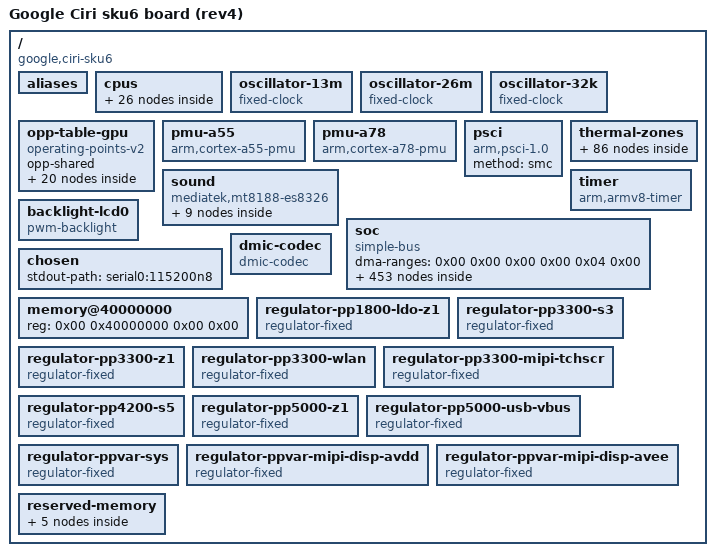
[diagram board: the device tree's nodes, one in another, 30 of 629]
/dts-v1/;

/ {
	compatible = "google,ciri-sku6", "google,ciri", "mediatek,mt8188";
	interrupt-parent = <0x01>;
	#address-cells = <0x02>;
	#size-cells = <0x02>;
	model = "Google Ciri sku6 board (rev4)";

	aliases {
		dp-intf0 = "/soc/dp-intf@1c015000";
		dp-intf1 = "/soc/dp-intf@1c113000";
		dsc0 = "/soc/dsc@1c009000";
		ethdr0 = "/soc/ethdr@1c114000";
		gce0 = "/soc/mailbox@10320000";
		gce1 = "/soc/mailbox@10330000";
		merge0 = "/soc/merge0@1c014000";
		merge1 = "/soc/merge@1c10c000";
		merge2 = "/soc/merge@1c10d000";
		merge3 = "/soc/merge@1c10e000";
		merge4 = "/soc/merge@1c10f000";
		merge5 = "/soc/merge@1c110000";
		mutex0 = "/soc/mutex@1c016000";
		mutex1 = "/soc/mutex@1c101000";
		padding0 = "/soc/padding@1c11d000";
		padding1 = "/soc/padding@1c11e000";
		padding2 = "/soc/padding@1c11f000";
		padding3 = "/soc/padding@1c120000";
		padding4 = "/soc/padding@1c121000";
		padding5 = "/soc/padding@1c122000";
		padding6 = "/soc/padding@1c123000";
		padding7 = "/soc/padding@1c124000";
		vdo1-rdma0 = "/soc/rdma@1c104000";
		vdo1-rdma1 = "/soc/rdma@1c105000";
		vdo1-rdma2 = "/soc/rdma@1c106000";
		vdo1-rdma3 = "/soc/rdma@1c107000";
		vdo1-rdma4 = "/soc/rdma@1c108000";
		vdo1-rdma5 = "/soc/rdma@1c109000";
		vdo1-rdma6 = "/soc/rdma@1c10a000";
		vdo1-rdma7 = "/soc/rdma@1c10b000";
		dsi0 = "/soc/dsi@1c008000";
		i2c0 = "/soc/i2c@11280000";
		i2c1 = "/soc/i2c@11e00000";
		i2c2 = "/soc/i2c@11281000";
		i2c3 = "/soc/i2c@11282000";
		i2c4 = "/soc/i2c@11e01000";
		i2c5 = "/soc/i2c@11ec0000";
		i2c6 = "/soc/i2c@11ec1000";
		mmc0 = "/soc/mmc@11230000";
		serial0 = "/soc/serial@11001100";
	};

	cpus {
		#address-cells = <0x01>;
		#size-cells = <0x00>;

		cpu@0 {
			device_type = "cpu";
			compatible = "arm,cortex-a55";
			reg = <0x00>;
			enable-method = "psci";
			clock-frequency = <0x77359400>;
			capacity-dmips-mhz = <0x11a>;
			cpu-idle-states = <0x02 0x03>;
			i-cache-size = <0x8000>;
			i-cache-line-size = <0x40>;
			i-cache-sets = <0x80>;
			d-cache-size = <0x8000>;
			d-cache-line-size = <0x40>;
			d-cache-sets = <0x80>;
			next-level-cache = <0x04>;
			performance-domains = <0x05 0x00>;
			#cooling-cells = <0x02>;
			phandle = <0x09>;
		};

		cpu@100 {
			device_type = "cpu";
			compatible = "arm,cortex-a55";
			reg = <0x100>;
			enable-method = "psci";
			clock-frequency = <0x77359400>;
			capacity-dmips-mhz = <0x11a>;
			cpu-idle-states = <0x02 0x03>;
			i-cache-size = <0x8000>;
			i-cache-line-size = <0x40>;
			i-cache-sets = <0x80>;
			d-cache-size = <0x8000>;
			d-cache-line-size = <0x40>;
			d-cache-sets = <0x80>;
			next-level-cache = <0x04>;
			performance-domains = <0x05 0x00>;
			#cooling-cells = <0x02>;
			phandle = <0x0a>;
		};

		cpu@200 {
			device_type = "cpu";
			compatible = "arm,cortex-a55";
			reg = <0x200>;
			enable-method = "psci";
			clock-frequency = <0x77359400>;
			capacity-dmips-mhz = <0x11a>;
			cpu-idle-states = <0x02 0x03>;
			i-cache-size = <0x8000>;
			i-cache-line-size = <0x40>;
			i-cache-sets = <0x80>;
			d-cache-size = <0x8000>;
			d-cache-line-size = <0x40>;
			d-cache-sets = <0x80>;
			next-level-cache = <0x04>;
			performance-domains = <0x05 0x00>;
			#cooling-cells = <0x02>;
			phandle = <0x0b>;
		};

		cpu@300 {
			device_type = "cpu";
			compatible = "arm,cortex-a55";
			reg = <0x300>;
			enable-method = "psci";
			clock-frequency = <0x77359400>;
			capacity-dmips-mhz = <0x11a>;
			cpu-idle-states = <0x02 0x03>;
			i-cache-size = <0x8000>;
			i-cache-line-size = <0x40>;
			i-cache-sets = <0x80>;
			d-cache-size = <0x8000>;
			d-cache-line-size = <0x40>;
			d-cache-sets = <0x80>;
			next-level-cache = <0x04>;
			performance-domains = <0x05 0x00>;
			#cooling-cells = <0x02>;
			phandle = <0x0c>;
		};

		cpu@400 {
			device_type = "cpu";
			compatible = "arm,cortex-a55";
			reg = <0x400>;
			enable-method = "psci";
			clock-frequency = <0x77359400>;
			capacity-dmips-mhz = <0x11a>;
			cpu-idle-states = <0x02 0x03>;
			i-cache-size = <0x8000>;
			i-cache-line-size = <0x40>;
			i-cache-sets = <0x80>;
			d-cache-size = <0x8000>;
			d-cache-line-size = <0x40>;
			d-cache-sets = <0x80>;
			next-level-cache = <0x04>;
			performance-domains = <0x05 0x00>;
			#cooling-cells = <0x02>;
			phandle = <0x0d>;
		};

		cpu@500 {
			device_type = "cpu";
			compatible = "arm,cortex-a55";
			reg = <0x500>;
			enable-method = "psci";
			clock-frequency = <0x77359400>;
			capacity-dmips-mhz = <0x11a>;
			cpu-idle-states = <0x02 0x03>;
			i-cache-size = <0x8000>;
			i-cache-line-size = <0x40>;
			i-cache-sets = <0x80>;
			d-cache-size = <0x8000>;
			d-cache-line-size = <0x40>;
			d-cache-sets = <0x80>;
			next-level-cache = <0x04>;
			performance-domains = <0x05 0x00>;
			#cooling-cells = <0x02>;
			phandle = <0x0e>;
		};

		cpu@600 {
			device_type = "cpu";
			compatible = "arm,cortex-a78";
			reg = <0x600>;
			enable-method = "psci";
			clock-frequency = <0x9af8da00>;
			capacity-dmips-mhz = <0x400>;
			cpu-idle-states = <0x06 0x07>;
			i-cache-size = <0x10000>;
			i-cache-line-size = <0x40>;
			i-cache-sets = <0x100>;
			d-cache-size = <0x10000>;
			d-cache-line-size = <0x40>;
			d-cache-sets = <0x100>;
			next-level-cache = <0x08>;
			performance-domains = <0x05 0x01>;
			#cooling-cells = <0x02>;
			phandle = <0x0f>;
		};

		cpu@700 {
			device_type = "cpu";
			compatible = "arm,cortex-a78";
			reg = <0x700>;
			enable-method = "psci";
			clock-frequency = <0x9af8da00>;
			capacity-dmips-mhz = <0x400>;
			cpu-idle-states = <0x06 0x07>;
			i-cache-size = <0x10000>;
			i-cache-line-size = <0x40>;
			i-cache-sets = <0x100>;
			d-cache-size = <0x10000>;
			d-cache-line-size = <0x40>;
			d-cache-sets = <0x100>;
			next-level-cache = <0x08>;
			performance-domains = <0x05 0x01>;
			#cooling-cells = <0x02>;
			phandle = <0x10>;
		};

		cpu-map {

			cluster0 {

				core0 {
					cpu = <0x09>;
				};

				core1 {
					cpu = <0x0a>;
				};

				core2 {
					cpu = <0x0b>;
				};

				core3 {
					cpu = <0x0c>;
				};

				core4 {
					cpu = <0x0d>;
				};

				core5 {
					cpu = <0x0e>;
				};

				core6 {
					cpu = <0x0f>;
				};

				core7 {
					cpu = <0x10>;
				};
			};
		};

		idle-states {
			entry-method = "psci";

			cpu-off-l {
				compatible = "arm,idle-state";
				arm,psci-suspend-param = <0x10000>;
				local-timer-stop;
				entry-latency-us = <0x32>;
				exit-latency-us = <0x5f>;
				min-residency-us = <0x244>;
				phandle = <0x02>;
			};

			cpu-off-b {
				compatible = "arm,idle-state";
				arm,psci-suspend-param = <0x10000>;
				local-timer-stop;
				entry-latency-us = <0x2d>;
				exit-latency-us = <0x8c>;
				min-residency-us = <0x2e4>;
				phandle = <0x06>;
			};

			cluster-off-l {
				compatible = "arm,idle-state";
				arm,psci-suspend-param = <0x1010010>;
				local-timer-stop;
				entry-latency-us = <0x37>;
				exit-latency-us = <0x9b>;
				min-residency-us = <0x348>;
				phandle = <0x03>;
			};

			cluster-off-b {
				compatible = "arm,idle-state";
				arm,psci-suspend-param = <0x1010010>;
				local-timer-stop;
				entry-latency-us = <0x32>;
				exit-latency-us = <0xc8>;
				min-residency-us = <0x3e8>;
				phandle = <0x07>;
			};
		};

		l2-cache0 {
			compatible = "cache";
			cache-level = <0x02>;
			cache-size = <0x20000>;
			cache-line-size = <0x40>;
			cache-sets = <0x200>;
			next-level-cache = <0x11>;
			cache-unified;
			phandle = <0x04>;
		};

		l2-cache1 {
			compatible = "cache";
			cache-level = <0x02>;
			cache-size = <0x40000>;
			cache-line-size = <0x40>;
			cache-sets = <0x200>;
			next-level-cache = <0x11>;
			cache-unified;
			phandle = <0x08>;
		};

		l3-cache {
			compatible = "cache";
			cache-level = <0x03>;
			cache-size = <0x200000>;
			cache-line-size = <0x40>;
			cache-sets = <0x800>;
			cache-unified;
			phandle = <0x11>;
		};
	};

	oscillator-13m {
		compatible = "fixed-clock";
		#clock-cells = <0x00>;
		clock-frequency = <0xc65d40>;
		clock-output-names = "clk13m";
		phandle = <0x40>;
	};

	oscillator-26m {
		compatible = "fixed-clock";
		#clock-cells = <0x00>;
		clock-frequency = <0x18cba80>;
		clock-output-names = "clk26m";
		phandle = <0x43>;
	};

	oscillator-32k {
		compatible = "fixed-clock";
		#clock-cells = <0x00>;
		clock-frequency = <0x8000>;
		clock-output-names = "clk32k";
	};

	opp-table-gpu {
		compatible = "operating-points-v2";
		opp-shared;
		phandle = <0x77>;

		opp-390000000 {
			opp-hz = <0x00 0x173eed80>;
			opp-microvolt = <0x8c618>;
			opp-supported-hw = <0xff>;
		};

		opp-431000000 {
			opp-hz = <0x00 0x19b089c0>;
			opp-microvolt = <0x8f6ec>;
			opp-supported-hw = <0xff>;
		};

		opp-473000000 {
			opp-hz = <0x00 0x1c316840>;
			opp-microvolt = <0x927c0>;
			opp-supported-hw = <0xff>;
		};

		opp-515000000 {
			opp-hz = <0x00 0x1eb246c0>;
			opp-microvolt = <0x95894>;
			opp-supported-hw = <0xff>;
		};

		opp-556000000 {
			opp-hz = <0x00 0x2123e300>;
			opp-microvolt = <0x98968>;
			opp-supported-hw = <0xff>;
		};

		opp-598000000 {
			opp-hz = <0x00 0x23a4c180>;
			opp-microvolt = <0x9ba3c>;
			opp-supported-hw = <0xff>;
		};

		opp-640000000 {
			opp-hz = <0x00 0x2625a000>;
			opp-microvolt = <0x9eb10>;
			opp-supported-hw = <0xff>;
		};

		opp-670000000 {
			opp-hz = <0x00 0x27ef6380>;
			opp-microvolt = <0xa1be4>;
			opp-supported-hw = <0xff>;
		};

		opp-700000000 {
			opp-hz = <0x00 0x29b92700>;
			opp-microvolt = <0xa4cb8>;
			opp-supported-hw = <0xff>;
		};

		opp-730000000 {
			opp-hz = <0x00 0x2b82ea80>;
			opp-microvolt = <0xa7d8c>;
			opp-supported-hw = <0xff>;
		};

		opp-760000000 {
			opp-hz = <0x00 0x2d4cae00>;
			opp-microvolt = <0xaae60>;
			opp-supported-hw = <0xff>;
		};

		opp-790000000 {
			opp-hz = <0x00 0x2f167180>;
			opp-microvolt = <0xadf34>;
			opp-supported-hw = <0xff>;
		};

		opp-835000000 {
			opp-hz = <0x00 0x31c516c0>;
			opp-microvolt = <0xb2872>;
			opp-supported-hw = <0xff>;
		};

		opp-880000000 {
			opp-hz = <0x00 0x3473bc00>;
			opp-microvolt = <0xb71b0>;
			opp-supported-hw = <0xff>;
		};

		opp-915000000 {
			opp-hz = <0x00 0x3689cac0>;
			opp-microvolt = <0xbd358>;
			opp-supported-hw = <0x8f>;
		};

		opp-915000000-5 {
			opp-hz = <0x00 0x3689cac0>;
			opp-microvolt = <0xba284>;
			opp-supported-hw = <0x30>;
		};

		opp-915000000-6 {
			opp-hz = <0x00 0x3689cac0>;
			opp-microvolt = <0xb71b0>;
			opp-supported-hw = <0x70>;
		};

		opp-950000000 {
			opp-hz = <0x00 0x389fd980>;
			opp-microvolt = <0xf5000>;
			opp-supported-hw = <0x8f>;
		};

		opp-950000000-5 {
			opp-hz = <0x00 0x389fd980>;
			opp-microvolt = <0xbd358>;
			opp-supported-hw = <0x30>;
		};

		opp-950000000-6 {
			opp-hz = <0x00 0x389fd980>;
			opp-microvolt = <0xb71b0>;
			opp-supported-hw = <0x70>;
		};
	};

	pmu-a55 {
		compatible = "arm,cortex-a55-pmu";
		interrupt-parent = <0x01>;
		interrupts = <0x01 0x07 0x04 0x12>;
	};

	pmu-a78 {
		compatible = "arm,cortex-a78-pmu";
		interrupt-parent = <0x01>;
		interrupts = <0x01 0x07 0x04 0x13>;
	};

	psci {
		compatible = "arm,psci-1.0";
		method = "smc";
	};

	sound {
		mediatek,platform = <0x14>;
		status = "okay";
		pinctrl-names = "aud_etdm_hp_on", "aud_etdm_hp_off", "aud_etdm_spk_on", "aud_etdm_spk_off", "aud_mtkaif_on", "aud_mtkaif_off";
		pinctrl-0 = <0x15>;
		pinctrl-1 = <0x16>;
		pinctrl-2 = <0x17>;
		pinctrl-3 = <0x18>;
		pinctrl-4 = <0x19>;
		pinctrl-5 = <0x1a>;
		mediatek,adsp = <0x1b>;
		compatible = "mediatek,mt8188-es8326";
		model = "mt8188_tas2563_8326";
		audio-routing = "ETDM1_OUT", "ETDM_SPK_PIN", "ETDM2_OUT", "ETDM_HP_PIN", "ETDM1_IN", "ETDM_SPK_PIN", "ETDM2_IN", "ETDM_HP_PIN", "ADDA Capture", "MTKAIF_PIN", "Headphone Jack", "HPOL", "Headphone Jack", "HPOR", "MIC1", "Headset Mic";

		dai-link-0 {
			link-name = "ETDM2_OUT_BE";
			mediatek,clk-provider = "cpu";

			codec {
				sound-dai = <0x1d>;
			};
		};

		dai-link-1 {
			link-name = "ETDM2_IN_BE";
			mediatek,clk-provider = "cpu";

			codec {
				sound-dai = <0x1d>;
			};
		};

		dai-link-2 {
			link-name = "ETDM1_OUT_BE";
			dai-format = "i2s";
			mediatek,clk-provider = "cpu";

			codec {
				sound-dai = <0x1c>;
			};
		};

		dai-link-3 {
			link-name = "ETDM1_IN_BE";
			dai-format = "i2s";
			mediatek,clk-provider = "cpu";
		};

		dai-link-4 {
			link-name = "DPTX_BE";

			codec {
				sound-dai = <0x1e>;
			};
		};
	};

	thermal-zones {

		cpu-little0-thermal {
			polling-delay = <0x3e8>;
			polling-delay-passive = <0x96>;
			thermal-sensors = <0x1f 0x00>;

			trips {

				trip-alert0 {
					temperature = <0x15f90>;
					hysteresis = <0x7d0>;
					type = "passive";
					phandle = <0x20>;
				};

				trip-alert1 {
					temperature = <0x17318>;
					hysteresis = <0x7d0>;
					type = "hot";
				};

				trip-crit {
					temperature = <0x186a0>;
					hysteresis = <0x00>;
					type = "critical";
				};
			};

			cooling-maps {

				map0 {
					trip = <0x20>;
					cooling-device = <0x09 0xffffffff 0xffffffff 0x0a 0xffffffff 0xffffffff 0x0b 0xffffffff 0xffffffff 0x0c 0xffffffff 0xffffffff 0x0d 0xffffffff 0xffffffff 0x0e 0xffffffff 0xffffffff>;
				};
			};
		};

		cpu-little1-thermal {
			polling-delay = <0x3e8>;
			polling-delay-passive = <0x96>;
			thermal-sensors = <0x1f 0x01>;

			trips {

				trip-alert0 {
					temperature = <0x15f90>;
					hysteresis = <0x7d0>;
					type = "passive";
					phandle = <0x21>;
				};

				trip-alert1 {
					temperature = <0x17318>;
					hysteresis = <0x7d0>;
					type = "hot";
				};

				trip-crit {
					temperature = <0x186a0>;
					hysteresis = <0x00>;
					type = "critical";
				};
			};

			cooling-maps {

				map0 {
					trip = <0x21>;
					cooling-device = <0x09 0xffffffff 0xffffffff 0x0a 0xffffffff 0xffffffff 0x0b 0xffffffff 0xffffffff 0x0c 0xffffffff 0xffffffff 0x0d 0xffffffff 0xffffffff 0x0e 0xffffffff 0xffffffff>;
				};
			};
		};

		cpu-little2-thermal {
			polling-delay = <0x3e8>;
			polling-delay-passive = <0x96>;
			thermal-sensors = <0x1f 0x02>;

			trips {

				trip-alert0 {
					temperature = <0x15f90>;
					hysteresis = <0x7d0>;
					type = "passive";
					phandle = <0x22>;
				};

				trip-alert1 {
					temperature = <0x17318>;
					hysteresis = <0x7d0>;
					type = "hot";
				};

				trip-crit {
					temperature = <0x186a0>;
					hysteresis = <0x00>;
					type = "critical";
				};
			};

			cooling-maps {

				map0 {
					trip = <0x22>;
					cooling-device = <0x09 0xffffffff 0xffffffff 0x0a 0xffffffff 0xffffffff 0x0b 0xffffffff 0xffffffff 0x0c 0xffffffff 0xffffffff 0x0d 0xffffffff 0xffffffff 0x0e 0xffffffff 0xffffffff>;
				};
			};
		};

		cpu-little3-thermal {
			polling-delay = <0x3e8>;
			polling-delay-passive = <0x96>;
			thermal-sensors = <0x1f 0x03>;

			trips {

				trip-alert0 {
					temperature = <0x15f90>;
					hysteresis = <0x7d0>;
					type = "passive";
					phandle = <0x23>;
				};

				trip-alert1 {
					temperature = <0x17318>;
					hysteresis = <0x7d0>;
					type = "hot";
				};

				trip-crit {
					temperature = <0x186a0>;
					hysteresis = <0x00>;
					type = "critical";
				};
			};

			cooling-maps {

				map0 {
					trip = <0x23>;
					cooling-device = <0x09 0xffffffff 0xffffffff 0x0a 0xffffffff 0xffffffff 0x0b 0xffffffff 0xffffffff 0x0c 0xffffffff 0xffffffff 0x0d 0xffffffff 0xffffffff 0x0e 0xffffffff 0xffffffff>;
				};
			};
		};

		cpu-big0-thermal {
			polling-delay = <0x3e8>;
			polling-delay-passive = <0x64>;
			thermal-sensors = <0x1f 0x04>;

			trips {

				trip-alert0 {
					temperature = <0x15f90>;
					hysteresis = <0x7d0>;
					type = "passive";
					phandle = <0x24>;
				};

				trip-alert1 {
					temperature = <0x17318>;
					hysteresis = <0x7d0>;
					type = "hot";
				};

				trip-crit {
					temperature = <0x186a0>;
					hysteresis = <0x00>;
					type = "critical";
				};
			};

			cooling-maps {

				map0 {
					trip = <0x24>;
					cooling-device = <0x0f 0xffffffff 0xffffffff 0x10 0xffffffff 0xffffffff>;
				};
			};
		};

		cpu-big1-thermal {
			polling-delay = <0x3e8>;
			polling-delay-passive = <0x64>;
			thermal-sensors = <0x1f 0x05>;

			trips {

				trip-alert0 {
					temperature = <0x15f90>;
					hysteresis = <0x7d0>;
					type = "passive";
					phandle = <0x25>;
				};

				trip-alert1 {
					temperature = <0x17318>;
					hysteresis = <0x7d0>;
					type = "hot";
				};

				trip-crit {
					temperature = <0x186a0>;
					hysteresis = <0x00>;
					type = "critical";
				};
			};

			cooling-maps {

				map0 {
					trip = <0x25>;
					cooling-device = <0x0f 0xffffffff 0xffffffff 0x10 0xffffffff 0xffffffff>;
				};
			};
		};

		apu-thermal {
			polling-delay = <0x3e8>;
			polling-delay-passive = <0xfa>;
			thermal-sensors = <0x26 0x00>;

			trips {

				trip-alert0 {
					temperature = <0x14c08>;
					hysteresis = <0x7d0>;
					type = "passive";
				};

				trip-alert1 {
					temperature = <0x17318>;
					hysteresis = <0x7d0>;
					type = "hot";
				};

				trip-crit {
					temperature = <0x186a0>;
					hysteresis = <0x00>;
					type = "critical";
				};
			};
		};

		gpu-thermal {
			polling-delay = <0x3e8>;
			polling-delay-passive = <0xfa>;
			thermal-sensors = <0x26 0x01>;

			trips {

				trip-alert0 {
					temperature = <0x14c08>;
					hysteresis = <0x7d0>;
					type = "passive";
					phandle = <0x27>;
				};

				trip-alert1 {
					temperature = <0x17318>;
					hysteresis = <0x7d0>;
					type = "hot";
				};

				trip-crit {
					temperature = <0x186a0>;
					hysteresis = <0x00>;
					type = "critical";
				};
			};

			cooling-maps {

				map0 {
					trip = <0x27>;
					cooling-device = <0x28 0xffffffff 0xffffffff>;
				};
			};
		};

		gpu1-thermal {
			polling-delay = <0x3e8>;
			polling-delay-passive = <0xfa>;
			thermal-sensors = <0x26 0x02>;

			trips {

				trip-alert0 {
					temperature = <0x14c08>;
					hysteresis = <0x7d0>;
					type = "passive";
					phandle = <0x29>;
				};

				trip-alert1 {
					temperature = <0x17318>;
					hysteresis = <0x7d0>;
					type = "hot";
				};

				trip-crit {
					temperature = <0x186a0>;
					hysteresis = <0x00>;
					type = "critical";
				};
			};

			cooling-maps {

				map0 {
					trip = <0x29>;
					cooling-device = <0x28 0xffffffff 0xffffffff>;
				};
			};
		};

		adsp-thermal {
			polling-delay = <0x3e8>;
			polling-delay-passive = <0xfa>;
			thermal-sensors = <0x26 0x03>;

			trips {

				trip-alert0 {
					temperature = <0x14c08>;
					hysteresis = <0x7d0>;
					type = "passive";
				};

				trip-alert1 {
					temperature = <0x17318>;
					hysteresis = <0x7d0>;
					type = "hot";
				};

				trip-crit {
					temperature = <0x186a0>;
					hysteresis = <0x00>;
					type = "critical";
				};
			};
		};

		vdo-thermal {
			polling-delay = <0x3e8>;
			polling-delay-passive = <0xfa>;
			thermal-sensors = <0x26 0x04>;

			trips {

				trip-alert0 {
					temperature = <0x14c08>;
					hysteresis = <0x7d0>;
					type = "passive";
				};

				trip-alert1 {
					temperature = <0x17318>;
					hysteresis = <0x7d0>;
					type = "hot";
				};

				trip-crit {
					temperature = <0x186a0>;
					hysteresis = <0x00>;
					type = "critical";
				};
			};
		};

		infra-thermal {
			polling-delay = <0x3e8>;
			polling-delay-passive = <0xfa>;
			thermal-sensors = <0x26 0x05>;

			trips {

				trip-alert0 {
					temperature = <0x14c08>;
					hysteresis = <0x7d0>;
					type = "passive";
				};

				trip-alert1 {
					temperature = <0x17318>;
					hysteresis = <0x7d0>;
					type = "hot";
				};

				trip-crit {
					temperature = <0x186a0>;
					hysteresis = <0x00>;
					type = "critical";
				};
			};
		};

		cam1-thermal {
			polling-delay = <0x3e8>;
			polling-delay-passive = <0xfa>;
			thermal-sensors = <0x26 0x06>;

			trips {

				trip-alert0 {
					temperature = <0x14c08>;
					hysteresis = <0x7d0>;
					type = "passive";
				};

				trip-alert1 {
					temperature = <0x17318>;
					hysteresis = <0x7d0>;
					type = "hot";
				};

				trip-crit {
					temperature = <0x186a0>;
					hysteresis = <0x00>;
					type = "critical";
				};
			};
		};

		cam2-thermal {
			polling-delay = <0x3e8>;
			polling-delay-passive = <0xfa>;
			thermal-sensors = <0x26 0x07>;

			trips {

				trip-alert0 {
					temperature = <0x14c08>;
					hysteresis = <0x7d0>;
					type = "passive";
				};

				trip-alert1 {
					temperature = <0x17318>;
					hysteresis = <0x7d0>;
					type = "hot";
				};

				trip-crit {
					temperature = <0x186a0>;
					hysteresis = <0x00>;
					type = "critical";
				};
			};
		};
	};

	timer {
		compatible = "arm,armv8-timer";
		interrupt-parent = <0x01>;
		interrupts = <0x01 0x0d 0x04 0x00 0x01 0x0e 0x04 0x00 0x01 0x0b 0x04 0x00 0x01 0x0a 0x04 0x00>;
		clock-frequency = <0xc65d40>;
	};

	soc {
		#address-cells = <0x02>;
		#size-cells = <0x02>;
		compatible = "simple-bus";
		dma-ranges = <0x00 0x00 0x00 0x00 0x04 0x00>;
		ranges;

		performance-controller@11bc10 {
			compatible = "mediatek,cpufreq-hw";
			reg = <0x00 0x11bc10 0x00 0x120 0x00 0x11bd30 0x00 0x120>;
			#performance-domain-cells = <0x01>;
			phandle = <0x05>;
		};

		interrupt-controller@c000000 {
			compatible = "arm,gic-v3";
			#interrupt-cells = <0x04>;
			#redistributor-regions = <0x01>;
			interrupt-parent = <0x01>;
			interrupt-controller;
			reg = <0x00 0xc000000 0x00 0x40000 0x00 0xc040000 0x00 0x200000>;
			interrupts = <0x01 0x09 0x04 0x00>;
			phandle = <0x01>;

			ppi-partitions {

				interrupt-partition-0 {
					affinity = <0x09 0x0a 0x0b 0x0c 0x0d 0x0e>;
					phandle = <0x12>;
				};

				interrupt-partition-1 {
					affinity = <0x0f 0x10>;
					phandle = <0x13>;
				};
			};
		};

		syscon@10000000 {
			compatible = "mediatek,mt8188-topckgen", "syscon";
			reg = <0x00 0x10000000 0x00 0x1000>;
			#clock-cells = <0x01>;
			phandle = <0x2d>;
		};

		syscon@10001000 {
			compatible = "mediatek,mt8188-infracfg-ao", "syscon";
			reg = <0x00 0x10001000 0x00 0x1000>;
			#clock-cells = <0x01>;
			#reset-cells = <0x01>;
			phandle = <0x2e>;
		};

		syscon@10003000 {
			compatible = "mediatek,mt8188-pericfg", "syscon";
			reg = <0x00 0x10003000 0x00 0x1000>;
			#clock-cells = <0x01>;
			phandle = <0x57>;
		};

		pinctrl@10005000 {
			compatible = "mediatek,mt8188-pinctrl";
			reg = <0x00 0x10005000 0x00 0x1000 0x00 0x11c00000 0x00 0x1000 0x00 0x11e10000 0x00 0x1000 0x00 0x11e20000 0x00 0x1000 0x00 0x11ea0000 0x00 0x1000 0x00 0x1000b000 0x00 0x1000>;
			reg-names = "iocfg0", "iocfg_rm", "iocfg_lt", "iocfg_lm", "iocfg_rt", "eint";
			gpio-controller;
			#gpio-cells = <0x02>;
			gpio-ranges = <0x2a 0x00 0x00 0xb0>;
			interrupt-controller;
			interrupts = <0x00 0xeb 0x04 0x00>;
			#interrupt-cells = <0x02>;
			gpio-line-names = "GSC_AP_INT_ODL", "AP_DISP_BKLTEN", "", "EN_PPVAR_MIPI_DISP", "EN_PPVAR_MIPI_DISP_150MA", "TCHSCR_RST_1V8_L", "", "", "", "", "", "I2S_SPKR_DATAOUT", "EN_PP3300_WLAN_X", "WIFI_KILL_1V8_L", "BT_KILL_1V8_L", "AP_FLASH_WP_L", "", "", "WCAM_PWDN_L", "WCAM_RST_L", "UCAM_PWDM_L", "UCAM_RST_L", "WCAM_24M_CLK", "UCAM_24M_CLK", "MT6319_INT", "DISP_RST_1V8_L", "DSIO_DSI_TE", "", "TP", "MIPI_BL_PWM_1V8", "", "UART_AP_TX_GSC_RX", "UART_GSC_TX_AP_RX", "UART_SSPM_TX_DBGCON_RX", "UART_DBGCON_TX_SSPM_RX", "UART_ADSP_TX_DBGCON_RX", "UART_DBGCON_TX_ADSP_RX", "JTAG_AP_TMS", "JTAG_AP_TCK", "JTAG_AP_TDI", "JTAG_AP_TDO", "JTAG_AP_TRST", "AP_KPCOL0", "TP", "", "TP", "EC_AP_HPD_OD", "PCIE_WAKE_1V8_ODL", "PCIE_RST_1V8_L", "PCIE_CLKREQ_1V8_ODL", "", "", "", "", "", "AP_I2C_AUD_SCL_1V8", "AP_I2C_AUD_SDA_1V8", "AP_I2C_TPM_SCL_1V8", "AP_I2C_TPM_SDA_1V8", "AP_I2C_TCHSCR_SCL_1V8", "AP_I2C_TCHSCR_SDA_1V8", "AP_I2C_PMIC_SAR_SCL_1V8", "AP_I2C_PMIC_SAR_SDA_1V8", "AP_I2C_EC_HID_KB_SCL_1V8", "AP_I2C_EC_HID_KB_SDA_1V8", "AP_I2C_UCAM_SCL_1V8", "AP_I2C_UCAM_SDA_1V8", "AP_I2C_WCAM_SCL_1V8", "AP_I2C_WCAM_SDA_1V8", "SPI_AP_CS_EC_L", "SPI_AP_CLK_EC", "SPI_AP_DO_EC_DI", "SPI_AP_DI_EC_DO", "TP", "TP", "SPI_AP_CS_TCHSCR_L", "SPI_AP_CLK_TCHSCR", "SPI_AP_DO_TCHSCR_DI", "SPI_AP_DI_TCHSCR_DO", "TP", "TP", "TP", "TP", "", "", "", "TP", "", "", "", "", "", "PWRAP_SPI_CS_L", "PWRAP_SPI_CK", "PWRAP_SPI_MOSI", "PWRAP_SPI_MISO", "SRCLKENA0", "SRCLKENA1", "SCP_VREQ_VAO", "AP_RTC_CLK32K", "AP_PMIC_WDTRST_L", "AUD_CLK_MOSI", "AUD_SYNC_MOSI", "AUD_DAT_MOSI0", "AUD_DAT_MOSI1", "AUD_DAT_MISO0", "AUD_DAT_MISO1", "", "HP_INT_ODL", "SPKR_INT_ODL", "I2S_HP_DATAIN", "EN_SPKR", "I2S_SPKR_MCLK", "I2S_SPKR_BCLK", "I2S_HP_MCLK", "I2S_HP_BCLK", "I2S_HP_LRCK", "I2S_HP_DATAOUT", "RST_SPKR_L", "I2S_SPKR_LRCK", "I2S_SPKR_DATAIN", "", "", "", "", "SPI_AP_CLK_ROM", "SPI_AP_CS_ROM_L", "SPI_AP_DO_ROM_DI", "SPI_AP_DI_ROM_DO", "TP", "TP", "", "", "", "", "", "", "", "", "EN_PP2800A_UCAM_X", "EN_PP1200_UCAM_X", "EN_PP2800A_WCAM_X", "EN_PP1100_WCAM_X", "TCHSCR_INT_1V8_L", "", "MT7921_PMU_EN_1V8", "", "AP_EC_WARM_RST_REQ", "EC_AP_HID_INT_ODL", "EC_AP_INT_ODL", "AP_XHCI_INIT_DONE", "EMMC_DAT7", "EMMC_DAT6", "EMMC_DAT5", "EMMC_DAT4", "EMMC_RST_L", "EMMC_CMD", "EMMC_CLK", "EMMC_DAT3", "EMMC_DAT2", "EMMC_DAT1", "EMMC_DAT0", "EMMC_DSL", "", "", "", "", "", "", "", "", "USB3_HUB_RST_L", "EC_AP_RSVD0_ODL", "", "", "SPMI_SCL", "SPMI_SDA";
			phandle = <0x2a>;

			adsp-uart-pins {
				phandle = <0x4b>;

				pins-bus {
					pinmux = <0x2303 0x2403>;
				};
			};

			aud-etdm-hp-on-pins {
				phandle = <0x15>;

				pins-bus {
					pinmux = <0x6e01 0x7301 0x7401 0x7501>;
				};

				pins-mclk {
					pinmux = <0x7201>;
				};
			};

			aud-etdm-hp-off-pins {
				phandle = <0x16>;

				pins-bus {
					pinmux = <0x6e00 0x7300 0x7400 0x7500>;
					bias-pull-down;
					input-enable;
				};

				pins-mclk {
					pinmux = <0x7200>;
					bias-pull-down;
					input-enable;
				};
			};

			aud-etdm-spk-on-pins {
				phandle = <0x17>;

				pins-bus {
					pinmux = <0xb03 0x7104 0x7704 0x7804>;
					drive-strength = <0x08>;
				};
			};

			aud-etdm-spk-off-pins {
				phandle = <0x18>;

				pins-bus {
					pinmux = <0xb00 0x7100 0x7700 0x7800>;
					bias-pull-down;
					input-enable;
				};
			};

			aud-mtkaif-on-pins {
				phandle = <0x19>;

				pins-bus {
					pinmux = <0x6501 0x6601 0x6701 0x6801 0x6901 0x6a01>;
				};
			};

			aud-mtkaif-off-pins {
				phandle = <0x1a>;

				pins-bus {
					pinmux = <0x6500 0x6600 0x6700 0x6800 0x6900 0x6a00>;
					bias-pull-down;
					input-enable;
				};
			};

			cros-ec-int-pins {
				phandle = <0x4e>;

				pins-ec-ap-int-odl {
					pinmux = <0x9500>;
					input-enable;
				};
			};

			disp-pwm0-pins {
				phandle = <0x50>;

				pins-disp-pwm0 {
					pinmux = <0x1d01>;
					output-high;
				};
			};

			disp-pwm1-pins {
				phandle = <0x51>;

				pins-disp-pwm1 {
					pinmux = <0x1e01>;
					output-high;
				};
			};

			dp-tx-hpd-pins {
				phandle = <0xad>;

				pins-dp-tx-hpd {
					pinmux = <0x2e01>;
				};
			};

			gsc-int-pins {
				phandle = <0x70>;

				pins-gsc-ap-int-odl {
					pinmux = <0x00>;
					input-enable;
				};
			};

			i2c0-pins {
				phandle = <0x62>;

				pins-bus {
					pinmux = <0x3801 0x3701>;
				};
			};

			i2c1-pins {
				phandle = <0x6f>;

				pins-bus {
					pinmux = <0x3a01 0x3901>;
				};
			};

			i2c2-pins {
				phandle = <0x64>;

				pins-bus {
					pinmux = <0x3c01 0x3b01>;
					bias-disable;
					drive-strength = <0x0c>;
				};
			};

			i2c3-pins {
				phandle = <0x65>;

				pins-bus {
					pinmux = <0x3e01 0x3d01>;
				};
			};

			i2c4-pins {
				phandle = <0x71>;

				pins-bus {
					pinmux = <0x4001 0x3f01>;
				};
			};

			i2c5-pins {
				phandle = <0x73>;

				pins-bus {
					pinmux = <0x4201 0x4101>;
				};
			};

			i2c6-pins {
				phandle = <0x74>;

				pins-bus {
					pinmux = <0x4401 0x4301>;
				};
			};

			mipi-disp-avdd-en-pins {
				phandle = <0xb3>;

				pins-en-ppvar-mipi-disp {
					pinmux = <0x300>;
					output-low;
				};
			};

			mipi-disp-avee-en-pins {
				phandle = <0xb4>;

				pins-en-ppvar-mipi-disp-150ma {
					pinmux = <0x400>;
					output-low;
				};
			};

			mipi-dsi-pins {
				phandle = <0x94>;

				pins-bus {
					pinmux = <0x100 0x1900>;
					output-low;
				};
			};

			mmc0-default-pins {
				phandle = <0x5d>;

				pins-bus {
					pinmux = <0xa101 0xa001 0x9f01 0x9e01 0x9a01 0x9901 0x9801 0x9701 0x9c01>;
					input-enable;
					drive-strength = <0x06>;
					bias-pull-up = <0x65>;
				};

				pins-clk {
					pinmux = <0x9d01>;
					drive-strength = <0x06>;
					bias-pull-down = <0x66>;
				};

				pins-rst {
					pinmux = <0x9b01>;
					drive-strength = <0x06>;
					bias-pull-up = <0x65>;
				};
			};

			mmc0-uhs-pins {
				phandle = <0x5e>;

				pins-bus {
					pinmux = <0xa101 0xa001 0x9f01 0x9e01 0x9a01 0x9901 0x9801 0x9701 0x9c01>;
					input-enable;
					drive-strength = <0x08>;
					bias-pull-up = <0x65>;
				};

				pins-clk {
					pinmux = <0x9d01>;
					drive-strength = <0x08>;
					bias-pull-down = <0x66>;
				};

				pins-ds {
					pinmux = <0xa201>;
					drive-strength = <0x08>;
					bias-pull-down = <0x66>;
				};

				pins-rst {
					pinmux = <0x9b01>;
					drive-strength = <0x08>;
					bias-pull-up = <0x65>;
				};
			};

			nor-default-pins {
				phandle = <0x6d>;

				pins-clk {
					pinmux = <0x7f02 0x7d02 0x8002>;
					bias-pull-down;
				};

				pins-cs {
					pinmux = <0x7e02>;
					bias-pull-up;
				};
			};

			pcie-default-pins {
				phandle = <0x6c>;

				pins-bus {
					pinmux = <0x2f01 0x3001 0x3101>;
				};
			};

			scp-pins {
				phandle = <0x41>;

				pins-scp-vreq {
					pinmux = <0x6201>;
					bias-disable;
				};
			};

			spi0-pins {
				phandle = <0x4d>;

				pins-bus {
					pinmux = <0x4501 0x4601 0x4701 0x4801>;
					bias-disable;
				};
			};

			spi1-default-pins {
				phandle = <0x52>;

				pins-bus {
					pinmux = <0x4b01 0x4c01 0x4d01 0x4e01>;
					bias-disable;
				};
			};

			spi1-sleep-pins {
				phandle = <0x53>;

				pins-bus {
					pinmux = <0x4b00 0x4c00 0x4d00 0x4e00>;
					bias-pull-down;
					input-enable;
				};
			};

			spi2-pins {
				phandle = <0x54>;

				pins-bus {
					pinmux = <0x4f01 0x5001 0x5101 0x5201>;
					bias-disable;
				};
			};

			uart0-pins {
				phandle = <0x4c>;

				pins-bus {
					pinmux = <0x1f01 0x2001>;
					bias-pull-up;
				};
			};

			wlan-en-pins {
				phandle = <0xb1>;

				pins-en-pp3300-wlan {
					pinmux = <0xc00>;
					output-low;
				};
			};

			audio-codec-pins {
				phandle = <0x63>;

				pins-hp-int-odl {
					pinmux = <0x6c00>;
					input-enable;
				};
			};

			speaker-en-pins {

				pins-en-spkr {
					pinmux = <0x6f00>;
				};
			};

		};

		syscon@10006000 {
			compatible = "mediatek,mt8188-scpsys", "syscon", "simple-mfd";
			reg = <0x00 0x10006000 0x00 0x1000>;

			power-controller {
				compatible = "mediatek,mt8188-power-controller";
				#address-cells = <0x01>;
				#size-cells = <0x00>;
				#power-domain-cells = <0x01>;
				phandle = <0x44>;

				power-domain@0 {
					reg = <0x00>;
					#address-cells = <0x01>;
					#size-cells = <0x00>;
					#power-domain-cells = <0x01>;
					domain-supply = <0x2b>;

					power-domain@1 {
						reg = <0x01>;
						clocks = <0x2c 0x0e 0x2d 0x14>;
						clock-names = "mfg", "alt";
						mediatek,infracfg = <0x2e>;
						#address-cells = <0x01>;
						#size-cells = <0x00>;
						#power-domain-cells = <0x01>;
						domain-supply = <0x2f>;

						power-domain@2 {
							reg = <0x02>;
							#power-domain-cells = <0x00>;
						};

						power-domain@3 {
							reg = <0x03>;
							#power-domain-cells = <0x00>;
						};

						power-domain@4 {
							reg = <0x04>;
							#power-domain-cells = <0x00>;
						};
					};
				};

				power-domain@15 {
					reg = <0x0f>;
					clocks = <0x2d 0x04 0x2d 0x07 0x2d 0x08 0x2d 0x0a 0x2d 0x33 0x2d 0x34 0x2d 0x3d 0x2d 0xb9 0x2d 0xbe 0x30 0x0c 0x30 0x0d 0x30 0x0e 0x30 0x0f 0x30 0x10 0x30 0x11 0x30 0x12 0x30 0x13 0x30 0x14 0x30 0x15 0x30 0x16 0x30 0x17 0x30 0x1a 0x30 0x1b 0x30 0x1c 0x30 0x1d 0x30 0x1e 0x30 0x1f 0x30 0x20>;
					clock-names = "top", "cam", "ccu", "img", "venc", "vdec", "wpe", "cfgck", "cfgxo", "ss-sram-cmn", "ss-sram-v0l0", "ss-sram-v0l1", "ss-sram-ve0", "ss-sram-ve1", "ss-sram-ifa", "ss-sram-cam", "ss-sram-v1l5", "ss-sram-v1l6", "ss-sram-rdr", "ss-iommu", "ss-imgcam", "ss-emi", "ss-subcmn-rdr", "ss-rsi", "ss-cmn-l4", "ss-vdec1", "ss-wpe", "ss-cvdo-ve1";
					mediatek,infracfg = <0x2e>;
					#address-cells = <0x01>;
					#size-cells = <0x00>;
					#power-domain-cells = <0x01>;

					power-domain@16 {
						reg = <0x10>;
						clocks = <0x2d 0xbb 0x2d 0xc0 0x31 0x18 0x31 0x19 0x31 0x1a 0x31 0x1b 0x31 0x1c 0x31 0x1d 0x31 0x0f>;
						clock-names = "cfgck", "cfgxo", "ss-gals", "ss-cmn", "ss-emi", "ss-iommu", "ss-larb", "ss-rsi", "ss-bus";
						mediatek,infracfg = <0x2e>;
						#address-cells = <0x01>;
						#size-cells = <0x00>;
						#power-domain-cells = <0x01>;

						power-domain@20 {
							reg = <0x14>;
							clocks = <0x2d 0xba 0x2d 0xbf 0x32 0x1c 0x32 0x1d 0x32 0x1e 0x32 0x1f>;
							clock-names = "cfgck", "cfgxo", "ss-vpp1-g5", "ss-vpp1-g6", "ss-vpp1-l5", "ss-vpp1-l6";
							mediatek,infracfg = <0x2e>;
							#power-domain-cells = <0x00>;
						};

						power-domain@22 {
							reg = <0x16>;
							clocks = <0x33 0x00>;
							clock-names = "ss-vdec1-soc-l1";
							mediatek,infracfg = <0x2e>;
							#address-cells = <0x01>;
							#size-cells = <0x00>;
							#power-domain-cells = <0x01>;

							power-domain@23 {
								reg = <0x17>;
								clocks = <0x34 0x00>;
								clock-names = "ss-vdec2-l1";
								mediatek,infracfg = <0x2e>;
								#power-domain-cells = <0x00>;
							};
						};

						power-domain@29 {
							reg = <0x1d>;
							clocks = <0x2d 0x07 0x2d 0x08 0x2d 0x09 0x2d 0xbd>;
							clock-names = "cam", "ccu", "bus", "cfgck";
							mediatek,infracfg = <0x2e>;
							#address-cells = <0x01>;
							#size-cells = <0x00>;
							#power-domain-cells = <0x01>;
							domain-supply = <0x35>;

							power-domain@30 {
								reg = <0x1e>;
								clocks = <0x36 0x00 0x36 0x01 0x36 0x16 0x36 0x17 0x36 0x18>;
								clock-names = "ss-cam-l13", "ss-cam-l14", "ss-cam-mm0", "ss-cam-mm1", "ss-camsys";
								mediatek,infracfg = <0x2e>;
								#address-cells = <0x01>;
								#size-cells = <0x00>;
								#power-domain-cells = <0x01>;

								power-domain@32 {
									reg = <0x20>;
									clocks = <0x36 0x04 0x37 0x00 0x38 0x00>;
									clock-names = "ss-camb-sub", "ss-camb-raw", "ss-camb-yuv";
									#power-domain-cells = <0x00>;
								};

								power-domain@31 {
									reg = <0x1f>;
									clocks = <0x36 0x03 0x39 0x00 0x3a 0x00>;
									clock-names = "ss-cama-sub", "ss-cama-raw", "ss-cama-yuv";
									#power-domain-cells = <0x00>;
								};
							};
						};

						power-domain@17 {
							reg = <0x11>;
							clocks = <0x2d 0xbc 0x2d 0xc1 0x3b 0x00 0x3b 0x01 0x3b 0x02>;
							clock-names = "cfgck", "cfgxo", "ss-larb2", "ss-larb3", "ss-gals";
							mediatek,infracfg = <0x2e>;
							#address-cells = <0x01>;
							#size-cells = <0x00>;
							#power-domain-cells = <0x01>;

							power-domain@9 {
								reg = <0x09>;
								clocks = <0x2d 0x40 0x2d 0x3f>;
								clock-names = "bus", "hdcp";
								mediatek,infracfg = <0x2e>;
								#power-domain-cells = <0x00>;
							};

							power-domain@18 {
								reg = <0x12>;
								mediatek,infracfg = <0x2e>;
								#power-domain-cells = <0x00>;
							};

							power-domain@19 {
								reg = <0x13>;
								mediatek,infracfg = <0x2e>;
								#power-domain-cells = <0x00>;
							};
						};

						power-domain@24 {
							reg = <0x18>;
							clocks = <0x3c 0x00 0x3c 0x01 0x3c 0x05 0x3c 0x06>;
							clock-names = "ss-ve1-larb", "ss-ve1-core", "ss-ve1-gals", "ss-ve1-sram";
							mediatek,infracfg = <0x2e>;
							#power-domain-cells = <0x00>;
						};

						power-domain@21 {
							reg = <0x15>;
							clocks = <0x3d 0x01 0x3d 0x03>;
							clock-names = "ss-wpe-l7", "ss-wpe-l7pce";
							mediatek,infracfg = <0x2e>;
							#power-domain-cells = <0x00>;
						};
					};
				};

				power-domain@5 {
					reg = <0x05>;
					mediatek,infracfg = <0x2e>;
					clocks = <0x3e 0x0c>;
					clock-names = "ss-pextp-fmem";
					#power-domain-cells = <0x00>;
				};

				power-domain@7 {
					reg = <0x07>;
					clocks = <0x2d 0x30 0x2d 0x31>;
					clock-names = "seninf0", "seninf1";
					#power-domain-cells = <0x00>;
				};

				power-domain@6 {
					reg = <0x06>;
					#power-domain-cells = <0x00>;
				};

				power-domain@10 {
					reg = <0x0a>;
					clocks = <0x2d 0x45 0x2d 0x44>;
					clock-names = "bus", "main";
					mediatek,infracfg = <0x2e>;
					#address-cells = <0x01>;
					#size-cells = <0x00>;
					#power-domain-cells = <0x01>;

					power-domain@11 {
						reg = <0x0b>;
						mediatek,infracfg = <0x2e>;
						#address-cells = <0x01>;
						#size-cells = <0x00>;
						#power-domain-cells = <0x01>;

						power-domain@14 {
							reg = <0x0e>;
							clocks = <0x2d 0x46>;
							clock-names = "asm";
							mediatek,infracfg = <0x2e>;
							#power-domain-cells = <0x00>;
						};

						power-domain@13 {
							reg = <0x0d>;
							clocks = <0x2d 0x53 0x2d 0x1f 0x3f 0x00>;
							clock-names = "a1sys", "intbus", "adspck";
							mediatek,infracfg = <0x2e>;
							#power-domain-cells = <0x00>;
						};

						power-domain@12 {
							reg = <0x0c>;
							mediatek,infracfg = <0x2e>;
							#power-domain-cells = <0x00>;
						};
					};
				};

				power-domain@8 {
					reg = <0x08>;
					clocks = <0x3e 0x0b>;
					clock-names = "ethermac";
					mediatek,infracfg = <0x2e>;
					#power-domain-cells = <0x00>;
				};
			};
		};

		watchdog@10007000 {
			compatible = "mediatek,mt8188-wdt";
			reg = <0x00 0x10007000 0x00 0x100>;
			mediatek,disable-extrst;
			#reset-cells = <0x01>;
			phandle = <0x45>;
		};

		syscon@1000c000 {
			compatible = "mediatek,mt8188-apmixedsys", "syscon";
			reg = <0x00 0x1000c000 0x00 0x1000>;
			#clock-cells = <0x01>;
			phandle = <0x2c>;
		};

		timer@10017000 {
			compatible = "mediatek,mt8188-timer", "mediatek,mt6765-timer";
			reg = <0x00 0x10017000 0x00 0x1000>;
			interrupts = <0x00 0x109 0x04 0x00>;
			clocks = <0x40>;
		};

		pwrap@10024000 {
			compatible = "mediatek,mt8188-pwrap", "mediatek,mt8195-pwrap", "syscon";
			reg = <0x00 0x10024000 0x00 0x1000>;
			reg-names = "pwrap";
			interrupts = <0x00 0xf3 0x04 0x00>;
			clocks = <0x2e 0x01 0x2e 0x00>;
			clock-names = "spi", "wrap";

			pmic {
				compatible = "mediatek,mt6359";
				interrupt-controller;
				#interrupt-cells = <0x02>;
				#sound-dai-cells = <0x01>;
				interrupts-extended = <0x2a 0xde 0x04>;

				adc {
					compatible = "mediatek,mt6359-auxadc";
					#io-channel-cells = <0x01>;
				};

				audio-codec {
					compatible = "mediatek,mt6359-codec";
					mediatek,dmic-mode = <0x01>;
					mediatek,mic-type-0 = <0x02>;
					mediatek,mic-type-2 = <0x02>;
				};

				regulators {
					compatible = "mediatek,mt6359-regulator";

					buck_vs1 {
						regulator-name = "vs1";
						regulator-min-microvolt = <0xf5000>;
						regulator-max-microvolt = <0x2191c0>;
						regulator-enable-ramp-delay = <0x00>;
						regulator-always-on;
					};

					buck_vgpu11 {
						regulator-name = "vgpu11";
						regulator-min-microvolt = <0x61a80>;
						regulator-max-microvolt = <0x123716>;
						regulator-ramp-delay = <0x1388>;
						regulator-enable-ramp-delay = <0xc8>;
						regulator-allowed-modes = <0x00 0x01 0x02>;
						regulator-always-on;
					};

					buck_vmodem {
						regulator-name = "vmodem";
						regulator-min-microvolt = <0xbd358>;
						regulator-max-microvolt = <0xbd358>;
						regulator-ramp-delay = <0x2a08>;
						regulator-enable-ramp-delay = <0xc8>;
					};

					buck_vpu {
						regulator-name = "vpu";
						regulator-min-microvolt = <0x61a80>;
						regulator-max-microvolt = <0x123716>;
						regulator-ramp-delay = <0x1388>;
						regulator-enable-ramp-delay = <0xc8>;
						regulator-allowed-modes = <0x00 0x01 0x02>;
						regulator-always-on;
					};

					buck_vcore {
						regulator-name = "vcore";
						regulator-min-microvolt = <0x61a80>;
						regulator-max-microvolt = <0x13d620>;
						regulator-ramp-delay = <0x1388>;
						regulator-enable-ramp-delay = <0xc8>;
						regulator-allowed-modes = <0x00 0x01 0x02>;
						regulator-always-on;
					};

					buck_vs2 {
						regulator-name = "vs2";
						regulator-min-microvolt = <0xf5000>;
						regulator-max-microvolt = <0x186a00>;
						regulator-enable-ramp-delay = <0x00>;
						regulator-always-on;
					};

					buck_vpa {
						regulator-name = "vpa";
						regulator-min-microvolt = <0x7a120>;
						regulator-max-microvolt = <0x2f4d60>;
						regulator-enable-ramp-delay = <0x12c>;
					};

					buck_vproc2 {
						regulator-name = "ppvar_dvdd_vgpu";
						regulator-min-microvolt = <0x86470>;
						regulator-max-microvolt = <0xf5000>;
						regulator-ramp-delay = <0x1d4c>;
						regulator-enable-ramp-delay = <0xc8>;
						regulator-allowed-modes = <0x00 0x01 0x02>;
						regulator-coupled-with = <0x2f>;
						regulator-coupled-max-spread = <0x186a>;
						phandle = <0x2b>;
					};

					buck_vproc1 {
						regulator-name = "vproc1";
						regulator-min-microvolt = <0x61a80>;
						regulator-max-microvolt = <0x123716>;
						regulator-ramp-delay = <0x1d4c>;
						regulator-enable-ramp-delay = <0xc8>;
						regulator-allowed-modes = <0x00 0x01 0x02>;
						phandle = <0x35>;
					};

					buck_vcore_sshub {
						regulator-name = "vcore_sshub";
						regulator-min-microvolt = <0x61a80>;
						regulator-max-microvolt = <0x123716>;
					};

					buck_vgpu11_sshub {
						regulator-name = "vgpu11_sshub";
						regulator-min-microvolt = <0x86470>;
						regulator-max-microvolt = <0x86470>;
						regulator-always-on;
					};

					ldo_vaud18 {
						regulator-name = "vaud18";
						regulator-min-microvolt = <0x1b7740>;
						regulator-max-microvolt = <0x1b7740>;
						regulator-enable-ramp-delay = <0xf0>;
					};

					ldo_vsim1 {
						regulator-name = "vsim1";
						regulator-min-microvolt = <0x19f0a0>;
						regulator-max-microvolt = <0x2f4d60>;
					};

					ldo_vibr {
						regulator-name = "vibr";
						regulator-min-microvolt = <0x124f80>;
						regulator-max-microvolt = <0x325aa0>;
					};

					ldo_vrf12 {
						regulator-name = "vrf12";
						regulator-min-microvolt = <0x10c8e0>;
						regulator-max-microvolt = <0x13d620>;
						regulator-always-on;
					};

					ldo_vusb {
						regulator-name = "vusb";
						regulator-min-microvolt = <0x2dc6c0>;
						regulator-max-microvolt = <0x2dc6c0>;
						regulator-enable-ramp-delay = <0x3c0>;
						regulator-always-on;
					};

					ldo_vsram_proc2 {
						regulator-name = "vsram_proc2";
						regulator-min-microvolt = <0x7a120>;
						regulator-max-microvolt = <0x13bdb6>;
						regulator-ramp-delay = <0x1d4c>;
						regulator-enable-ramp-delay = <0xf0>;
						regulator-always-on;
					};

					ldo_vio18 {
						regulator-name = "vio18";
						regulator-min-microvolt = <0x19f0a0>;
						regulator-max-microvolt = <0x1cfde0>;
						regulator-enable-ramp-delay = <0x3c0>;
						regulator-always-on;
					};

					ldo_vcamio {
						regulator-name = "vcamio";
						regulator-min-microvolt = <0x19f0a0>;
						regulator-max-microvolt = <0x1cfde0>;
					};

					ldo_vcn18 {
						regulator-name = "vcn18";
						regulator-min-microvolt = <0x1b7740>;
						regulator-max-microvolt = <0x1b7740>;
						regulator-enable-ramp-delay = <0xf0>;
					};

					ldo_vfe28 {
						regulator-name = "vfe28";
						regulator-min-microvolt = <0x2ab980>;
						regulator-max-microvolt = <0x2ab980>;
						regulator-enable-ramp-delay = <0x78>;
					};

					ldo_vcn13 {
						regulator-name = "vcn13";
						regulator-min-microvolt = <0xdbba0>;
						regulator-max-microvolt = <0x13d620>;
					};

					ldo_vcn33_1_bt {
						regulator-name = "vcn33_1_bt";
						regulator-min-microvolt = <0x2ab980>;
						regulator-max-microvolt = <0x3567e0>;
					};

					ldo_vcn33_1_wifi {
						regulator-name = "vcn33_1_wifi";
						regulator-min-microvolt = <0x2ab980>;
						regulator-max-microvolt = <0x3567e0>;
					};

					ldo_vaux18 {
						regulator-name = "vaux18";
						regulator-min-microvolt = <0x1b7740>;
						regulator-max-microvolt = <0x1b7740>;
						regulator-enable-ramp-delay = <0xf0>;
						regulator-always-on;
					};

					ldo_vsram_others {
						regulator-name = "pp0850_dvdd_sram_gpu";
						regulator-min-microvolt = <0xb71b0>;
						regulator-max-microvolt = <0xf5000>;
						regulator-ramp-delay = <0x1388>;
						regulator-enable-ramp-delay = <0xf0>;
						regulator-coupled-with = <0x2b>;
						regulator-coupled-max-spread = <0x186a>;
						phandle = <0x2f>;
					};

					ldo_vefuse {
						regulator-name = "vefuse";
						regulator-min-microvolt = <0x19f0a0>;
						regulator-max-microvolt = <0x1e8480>;
					};

					ldo_vxo22 {
						regulator-name = "vxo22";
						regulator-min-microvolt = <0x1b7740>;
						regulator-max-microvolt = <0x2191c0>;
						regulator-always-on;
					};

					ldo_vrfck {
						regulator-name = "vrfck";
						regulator-min-microvolt = <0x16e360>;
						regulator-max-microvolt = <0x19f0a0>;
					};

					ldo_vrfck_1 {
						regulator-name = "vrfck";
						regulator-min-microvolt = <0x12ebc0>;
						regulator-max-microvolt = <0x186a00>;
					};

					ldo_vbif28 {
						regulator-name = "vbif28";
						regulator-min-microvolt = <0x2ab980>;
						regulator-max-microvolt = <0x2ab980>;
						regulator-enable-ramp-delay = <0xf0>;
					};

					ldo_vio28 {
						regulator-name = "vio28";
						regulator-min-microvolt = <0x2ab980>;
						regulator-max-microvolt = <0x325aa0>;
					};

					ldo_vemc {
						regulator-name = "vemc";
						regulator-min-microvolt = <0x2c4020>;
						regulator-max-microvolt = <0x325aa0>;
					};

					ldo_vemc_1 {
						regulator-name = "vemc";
						regulator-min-microvolt = <0x2625a0>;
						regulator-max-microvolt = <0x325aa0>;
						phandle = <0x5f>;
					};

					ldo_vcn33_2_bt {
						regulator-name = "vcn33_2_bt";
						regulator-min-microvolt = <0x2ab980>;
						regulator-max-microvolt = <0x3567e0>;
					};

					ldo_vcn33_2_wifi {
						regulator-name = "vcn33_2_wifi";
						regulator-min-microvolt = <0x2ab980>;
						regulator-max-microvolt = <0x3567e0>;
					};

					ldo_va12 {
						regulator-name = "va12";
						regulator-min-microvolt = <0x124f80>;
						regulator-max-microvolt = <0x13d620>;
						regulator-always-on;
					};

					ldo_va09 {
						regulator-name = "va09";
						regulator-min-microvolt = <0xf5000>;
						regulator-max-microvolt = <0x124f80>;
					};

					ldo_vrf18 {
						regulator-name = "vrf18";
						regulator-min-microvolt = <0x19f0a0>;
						regulator-max-microvolt = <0x1b9e50>;
					};

					ldo_vsram_md {
						regulator-name = "vsram_md";
						regulator-min-microvolt = <0xf5000>;
						regulator-max-microvolt = <0xf5000>;
						regulator-ramp-delay = <0x2a08>;
						regulator-enable-ramp-delay = <0xf0>;
					};

					ldo_vufs {
						regulator-name = "vufs";
						regulator-min-microvolt = <0x19f0a0>;
						regulator-max-microvolt = <0x1cfde0>;
						regulator-always-on;
						phandle = <0x60>;
					};

					ldo_vm18 {
						regulator-name = "vm18";
						regulator-min-microvolt = <0x1b7740>;
						regulator-max-microvolt = <0x1cfde0>;
						regulator-microvolt-offset = <0x186a0>;
						phandle = <0x98>;
					};

					ldo_vbbck {
						regulator-name = "vbbck";
						regulator-min-microvolt = <0x10c8e0>;
						regulator-max-microvolt = <0x124f80>;
					};

					ldo_vsram_proc1 {
						regulator-name = "vsram_proc1";
						regulator-min-microvolt = <0x7a120>;
						regulator-max-microvolt = <0x13bdb6>;
						regulator-ramp-delay = <0x1d4c>;
						regulator-enable-ramp-delay = <0xf0>;
						regulator-always-on;
					};

					ldo_vsim2 {
						regulator-name = "vsim2";
						regulator-min-microvolt = <0x19f0a0>;
						regulator-max-microvolt = <0x2f4d60>;
					};

					ldo_vsram_others_sshub {
						regulator-name = "vsram_others_sshub";
						regulator-min-microvolt = <0x7a120>;
						regulator-max-microvolt = <0x13bdb6>;
					};
				};

				rtc {
					compatible = "mediatek,mt6358-rtc";
				};
			};
		};

		spmi@10027000 {
			compatible = "mediatek,mt8188-spmi", "mediatek,mt8195-spmi";
			reg = <0x00 0x10027000 0x00 0xe00 0x00 0x10029000 0x00 0x100>;
			reg-names = "pmif", "spmimst";
			assigned-clocks = <0x2d 0x38>;
			assigned-clock-parents = <0x2d 0xac>;
			clocks = <0x2e 0x01 0x2e 0x00 0x2d 0x38>;
			clock-names = "pmif_sys_ck", "pmif_tmr_ck", "spmimst_clk_mux";
		};

		iommu@10315000 {
			compatible = "mediatek,mt8188-iommu-infra";
			reg = <0x00 0x10315000 0x00 0x1000>;
			interrupts = <0x00 0x31b 0x04 0x00>;
			#iommu-cells = <0x01>;
			phandle = <0x6a>;
		};

		mailbox@10320000 {
			compatible = "mediatek,mt8188-gce";
			reg = <0x00 0x10320000 0x00 0x4000>;
			interrupts = <0x00 0xe2 0x04 0x00>;
			#mbox-cells = <0x02>;
			clocks = <0x2e 0x06>;
			phandle = <0x78>;
		};

		mailbox@10330000 {
			compatible = "mediatek,mt8188-gce";
			reg = <0x00 0x10330000 0x00 0x4000>;
			interrupts = <0x00 0xe4 0x04 0x00>;
			#mbox-cells = <0x02>;
			clocks = <0x2e 0x07>;
			phandle = <0x7a>;
		};

		scp@10720000 {
			compatible = "mediatek,mt8188-scp-dual";
			reg = <0x00 0x10720000 0x00 0xe0000>;
			reg-names = "cfg";
			#address-cells = <0x01>;
			#size-cells = <0x01>;
			ranges = <0x00 0x00 0x10500000 0x100000>;
			status = "okay";

			scp@0 {
				compatible = "mediatek,scp-core";
				reg = <0x00 0xd0000>;
				reg-names = "sram";
				interrupts = <0x00 0x1ce 0x04 0x00>;
				status = "okay";
				pinctrl-names = "default";
				pinctrl-0 = <0x41>;
				firmware-name = "mediatek/mt8188/scp.img";
				memory-region = <0x42>;
				phandle = <0x7b>;
			};

			scp@d0000 {
				compatible = "mediatek,scp-core";
				reg = <0xd0000 0x2f000>;
				reg-names = "sram";
				interrupts = <0x00 0x1cf 0x04 0x00>;
				status = "disabled";
			};
		};

		audio-controller@10b10000 {
			compatible = "mediatek,mt8188-afe";
			reg = <0x00 0x10b10000 0x00 0x10000>;
			assigned-clocks = <0x2d 0x53>;
			assigned-clock-parents = <0x2d 0x84>;
			clocks = <0x43 0x2c 0x09 0x2c 0x0a 0x2d 0xb3 0x2d 0xb4 0x2d 0xb5 0x2d 0xb6 0x2d 0xb8 0x2d 0x53 0x2d 0x1f 0x2d 0x20 0x2d 0x45 0x2d 0x51 0x2d 0x4d 0x2d 0x4e 0x2d 0x4f 0x2d 0x50 0x3f 0x00 0x2d 0x84 0x2d 0x86 0x2d 0xb7 0x2d 0x54 0x2d 0x52>;
			clock-names = "clk26m", "apll1", "apll2", "apll12_div0", "apll12_div1", "apll12_div2", "apll12_div3", "apll12_div9", "top_a1sys_hp", "top_aud_intbus", "top_audio_h", "top_audio_local_bus", "top_dptx", "top_i2so1", "top_i2so2", "top_i2si1", "top_i2si2", "adsp_audio_26m", "apll1_d4", "apll2_d4", "apll12_div4", "top_a2sys", "top_aud_iec";
			interrupts = <0x00 0x336 0x04 0x00>;
			power-domains = <0x44 0x0d>;
			resets = <0x45 0x0e>;
			reset-names = "audiosys";
			mediatek,infracfg = <0x2e>;
			mediatek,topckgen = <0x2d>;
			status = "okay";
			memory-region = <0x46>;
			mediatek,etdm-out1-cowork-source = <0x00>;
			mediatek,etdm-in2-cowork-source = <0x03>;
			phandle = <0x14>;
		};

		adsp@10b80000 {
			compatible = "mediatek,mt8188-dsp";
			reg = <0x00 0x10b80000 0x00 0x2000 0x00 0x10d00000 0x00 0x80000 0x00 0x10b8b000 0x00 0x100 0x00 0x10b8f000 0x00 0x1000>;
			reg-names = "cfg", "sram", "sec", "bus";
			assigned-clocks = <0x2d 0x44>;
			clocks = <0x2d 0x44 0x2d 0x45>;
			clock-names = "audiodsp", "adsp_bus";
			mboxes = <0x47 0x48>;
			mbox-names = "rx", "tx";
			power-domains = <0x44 0x0c>;
			status = "okay";
			memory-region = <0x49 0x4a>;
			pinctrl-names = "default";
			pinctrl-0 = <0x4b>;
			phandle = <0x1b>;
		};

		mailbox@10b86100 {
			compatible = "mediatek,mt8188-adsp-mbox", "mediatek,mt8186-adsp-mbox";
			reg = <0x00 0x10b86100 0x00 0x1000>;
			interrupts = <0x00 0x1de 0x04 0x00>;
			#mbox-cells = <0x00>;
			phandle = <0x47>;
		};

		mailbox@10b87100 {
			compatible = "mediatek,mt8188-adsp-mbox", "mediatek,mt8186-adsp-mbox";
			reg = <0x00 0x10b87100 0x00 0x1000>;
			interrupts = <0x00 0x1df 0x04 0x00>;
			#mbox-cells = <0x00>;
			phandle = <0x48>;
		};

		clock-controller@10b91100 {
			compatible = "mediatek,mt8188-adsp-audio26m";
			reg = <0x00 0x10b91100 0x00 0x100>;
			#clock-cells = <0x01>;
			phandle = <0x3f>;
		};

		serial@11001100 {
			compatible = "mediatek,mt8188-uart", "mediatek,mt6577-uart";
			reg = <0x00 0x11001100 0x00 0x100>;
			interrupts = <0x00 0x8d 0x04 0x00>;
			clocks = <0x43 0x2e 0x0f>;
			clock-names = "baud", "bus";
			status = "okay";
			pinctrl-names = "default";
			pinctrl-0 = <0x4c>;
		};

		serial@11001200 {
			compatible = "mediatek,mt8188-uart", "mediatek,mt6577-uart";
			reg = <0x00 0x11001200 0x00 0x100>;
			interrupts = <0x00 0x8e 0x04 0x00>;
			clocks = <0x43 0x2e 0x10>;
			clock-names = "baud", "bus";
			status = "disabled";
		};

		serial@11001300 {
			compatible = "mediatek,mt8188-uart", "mediatek,mt6577-uart";
			reg = <0x00 0x11001300 0x00 0x100>;
			interrupts = <0x00 0x8f 0x04 0x00>;
			clocks = <0x43 0x2e 0x11>;
			clock-names = "baud", "bus";
			status = "disabled";
		};

		serial@11001400 {
			compatible = "mediatek,mt8188-uart", "mediatek,mt6577-uart";
			reg = <0x00 0x11001400 0x00 0x100>;
			interrupts = <0x00 0x2d3 0x04 0x00>;
			clocks = <0x43 0x2e 0x12>;
			clock-names = "baud", "bus";
			status = "disabled";
		};

		adc@11002000 {
			compatible = "mediatek,mt8188-auxadc", "mediatek,mt8173-auxadc";
			reg = <0x00 0x11002000 0x00 0x1000>;
			clocks = <0x2e 0x1f>;
			clock-names = "main";
			#io-channel-cells = <0x01>;
			status = "okay";
		};

		syscon@11003000 {
			compatible = "mediatek,mt8188-pericfg-ao", "syscon";
			reg = <0x00 0x11003000 0x00 0x1000>;
			#clock-cells = <0x01>;
			phandle = <0x3e>;
		};

		spi@1100a000 {
			compatible = "mediatek,mt8188-spi-ipm", "mediatek,spi-ipm";
			#address-cells = <0x01>;
			#size-cells = <0x00>;
			reg = <0x00 0x1100a000 0x00 0x1000>;
			interrupts = <0x00 0xbf 0x04 0x00>;
			clocks = <0x2d 0x79 0x2d 0x19 0x2e 0x18>;
			clock-names = "parent-clk", "sel-clk", "spi-clk";
			status = "okay";
			pinctrl-names = "default";
			pinctrl-0 = <0x4d>;

			ec@0 {
				compatible = "google,cros-ec-spi";
				reg = <0x00>;
				interrupts-extended = <0x2a 0x95 0x08>;
				pinctrl-names = "default";
				pinctrl-0 = <0x4e>;
				spi-max-frequency = <0x2dc6c0>;

				i2c-tunnel {
					compatible = "google,cros-ec-i2c-tunnel";
					google,remote-bus = <0x01>;
					#address-cells = <0x01>;
					#size-cells = <0x00>;

					sbs-battery@f {
						compatible = "sbs,sbs-battery";
						reg = <0x0f>;
						sbs,i2c-retry-count = <0x02>;
						sbs,poll-retry-count = <0x01>;
					};
				};

				cbas {
					compatible = "google,cros-cbas";
				};

				keyboard-controller {
					compatible = "google,cros-ec-keyb";
					keypad,num-rows = <0x08>;
					keypad,num-columns = <0x0d>;
					google,needs-ghost-filter;
					linux,keymap = <0x2009e 0x30200ad 0x2020174 0x1020078 0x30400e0 0x20400e1 0x10400f8 0x2090071 0x1090072 0x40073 0x1007d 0x30030 0x50059 0x60031 0x8000d 0xa0064 0x1010001 0x1030022 0x1060023 0x1080028 0x10b000e 0x10c005c 0x200001d 0x201000f 0x2030014 0x205001b 0x2060015 0x2070056 0x208001a 0x20a007c 0x300007d 0x3010029 0x3030006 0x3060007 0x308000c 0x309008e 0x30b002b 0x30c005e 0x4000061 0x401001e 0x4020020 0x4030021 0x404001f 0x4050025 0x4060024 0x4080027 0x4090026 0x40a002b 0x40b001c 0x501002c 0x502002e 0x503002f 0x504002d 0x5050033 0x5060032 0x507002a 0x5080035 0x5090034 0x50b0039 0x6010002 0x6020004 0x6030005 0x6040003 0x6050009 0x6060008 0x608000b 0x609000a 0x60a0038 0x60b006c 0x60c006a 0x7010010 0x7020012 0x7030013 0x7040011 0x7050017 0x7060016 0x7070036 0x7080019 0x7090018 0x70b0067 0x70c0069>;
					function-row-physmap = <0x20000 0x3020000 0x2020000 0x1020000 0x3040000 0x2040000 0x1040000 0x2090000 0x1090000 0x40000>;
				};
			};
		};

		thermal-sensor@1100b000 {
			compatible = "mediatek,mt8188-lvts-ap";
			reg = <0x00 0x1100b000 0x00 0xc00>;
			interrupts = <0x00 0xc8 0x04 0x00>;
			clocks = <0x2e 0x08>;
			resets = <0x2e 0x01>;
			nvmem-cells = <0x4f>;
			nvmem-cell-names = "lvts-calib-data-1";
			#thermal-sensor-cells = <0x01>;
			phandle = <0x26>;
		};

		pwm@1100e000 {
			compatible = "mediatek,mt8188-disp-pwm", "mediatek,mt8183-disp-pwm";
			reg = <0x00 0x1100e000 0x00 0x1000>;
			clocks = <0x2d 0x27 0x2e 0x2f>;
			clock-names = "main", "mm";
			interrupts = <0x00 0xcb 0x04 0x00>;
			#pwm-cells = <0x02>;
			status = "okay";
			pinctrl-names = "default";
			pinctrl-0 = <0x50>;
			phandle = <0xb0>;
		};

		pwm@1100f000 {
			compatible = "mediatek,mt8188-disp-pwm", "mediatek,mt8183-disp-pwm";
			reg = <0x00 0x1100f000 0x00 0x1000>;
			clocks = <0x2d 0x28 0x2e 0x46>;
			clock-names = "main", "mm";
			interrupts = <0x00 0x319 0x04 0x00>;
			#pwm-cells = <0x02>;
			status = "disabled";
			pinctrl-names = "default";
			pinctrl-0 = <0x51>;
		};

		spi@11010000 {
			compatible = "mediatek,mt8188-spi-ipm", "mediatek,spi-ipm";
			#address-cells = <0x01>;
			#size-cells = <0x00>;
			reg = <0x00 0x11010000 0x00 0x1000>;
			interrupts = <0x00 0xc0 0x04 0x00>;
			clocks = <0x2d 0x79 0x2d 0x19 0x2e 0x32>;
			clock-names = "parent-clk", "sel-clk", "spi-clk";
			status = "okay";
			pinctrl-names = "default", "sleep";
			pinctrl-0 = <0x52>;
			pinctrl-1 = <0x53>;
			num-cs = <0x01>;

			touchscreen@0 {
				compatible = "himax,hx83102j";
				reg = <0x00>;
				spi-max-frequency = <0xbebc20>;
				interrupt-parent = <0x2a>;
				interrupts = <0x8f 0x08>;
				reset-gpios = <0x2a 0x05 0x01>;
				vdd-supply = <0xb6>;
				vddl-supply = <0x98>;
				firmware-name = "himax_i2chid_1002.bin";
			};

		};

		spi@11012000 {
			compatible = "mediatek,mt8188-spi-ipm", "mediatek,spi-ipm";
			#address-cells = <0x01>;
			#size-cells = <0x00>;
			reg = <0x00 0x11012000 0x00 0x1000>;
			interrupts = <0x00 0xc1 0x04 0x00>;
			clocks = <0x2d 0x79 0x2d 0x19 0x2e 0x33>;
			clock-names = "parent-clk", "sel-clk", "spi-clk";
			status = "okay";
			pinctrl-names = "default";
			pinctrl-0 = <0x54>;
		};

		spi@11013000 {
			compatible = "mediatek,mt8188-spi-ipm", "mediatek,spi-ipm";
			#address-cells = <0x01>;
			#size-cells = <0x00>;
			reg = <0x00 0x11013000 0x00 0x1000>;
			interrupts = <0x00 0xc2 0x04 0x00>;
			clocks = <0x2d 0x79 0x2d 0x19 0x2e 0x34>;
			clock-names = "parent-clk", "sel-clk", "spi-clk";
			status = "disabled";
		};

		spi@11018000 {
			compatible = "mediatek,mt8188-spi-ipm", "mediatek,spi-ipm";
			#address-cells = <0x01>;
			#size-cells = <0x00>;
			reg = <0x00 0x11018000 0x00 0x1000>;
			interrupts = <0x00 0xc3 0x04 0x00>;
			clocks = <0x2d 0x79 0x2d 0x19 0x2e 0x38>;
			clock-names = "parent-clk", "sel-clk", "spi-clk";
			status = "disabled";
		};

		spi@11019000 {
			compatible = "mediatek,mt8188-spi-ipm", "mediatek,spi-ipm";
			#address-cells = <0x01>;
			#size-cells = <0x00>;
			reg = <0x00 0x11019000 0x00 0x1000>;
			interrupts = <0x00 0xc4 0x04 0x00>;
			clocks = <0x2d 0x79 0x2d 0x19 0x2e 0x39>;
			clock-names = "parent-clk", "sel-clk", "spi-clk";
			status = "disabled";
		};

		usb@11201000 {
			compatible = "mediatek,mt8188-mtu3", "mediatek,mtu3";
			reg = <0x00 0x11201000 0x00 0x2dff 0x00 0x11203e00 0x00 0x100>;
			reg-names = "mac", "ippc";
			ranges = <0x00 0x00 0x00 0x11200000 0x00 0x3f00>;
			#address-cells = <0x02>;
			#size-cells = <0x02>;
			interrupts = <0x00 0x80 0x04 0x00>;
			assigned-clocks = <0x2d 0x29>;
			assigned-clock-parents = <0x2d 0x76>;
			clocks = <0x3e 0x09 0x2d 0xc5 0x3e 0x0a>;
			clock-names = "sys_ck", "ref_ck", "mcu_ck";
			phys = <0x55 0x03 0x56 0x04>;
			wakeup-source;
			mediatek,syscon-wakeup = <0x57 0x468 0x02>;
			status = "okay";
			dr_mode = "host";
			vusb33-supply = <0x58>;

			usb@0 {
				compatible = "mediatek,mt8188-xhci", "mediatek,mtk-xhci";
				reg = <0x00 0x00 0x00 0x1000>;
				reg-names = "mac";
				interrupts = <0x00 0x81 0x04 0x00>;
				assigned-clocks = <0x2d 0x2a>;
				assigned-clock-parents = <0x2d 0x76>;
				clocks = <0x3e 0x0a>;
				clock-names = "sys_ck";
				status = "okay";
				vusb33-supply = <0x58>;
				vbus-supply = <0x59>;
			};
		};

		ethernet@11021000 {
			compatible = "mediatek,mt8188-gmac", "mediatek,mt8195-gmac", "snps,dwmac-5.10a";
			reg = <0x00 0x11021000 0x00 0x4000>;
			interrupts = <0x00 0x2cc 0x04 0x00>;
			interrupt-names = "macirq";
			clocks = <0x3e 0x00 0x3e 0x01 0x2d 0x41 0x2d 0x42 0x2d 0x43 0x3e 0x0b>;
			clock-names = "axi", "apb", "mac_main", "ptp_ref", "rmii_internal", "mac_cg";
			assigned-clocks = <0x2d 0x41 0x2d 0x42 0x2d 0x43>;
			assigned-clock-parents = <0x2d 0xa0 0x2d 0xa2 0x2d 0xa3>;
			power-domains = <0x44 0x08>;
			mediatek,pericfg = <0x2e>;
			snps,axi-config = <0x5a>;
			snps,mtl-rx-config = <0x5b>;
			snps,mtl-tx-config = <0x5c>;
			snps,txpbl = <0x10>;
			snps,rxpbl = <0x10>;
			snps,clk-csr = <0x00>;
			status = "disabled";

			mdio {
				compatible = "snps,dwmac-mdio";
				#address-cells = <0x01>;
				#size-cells = <0x00>;
			};

			stmmac-axi-config {
				snps,blen = <0x00 0x00 0x00 0x00 0x10 0x08 0x04>;
				snps,rd_osr_lmt = <0x07>;
				snps,wr_osr_lmt = <0x07>;
				phandle = <0x5a>;
			};

			rx-queues-config {
				snps,rx-queues-to-use = <0x04>;
				snps,rx-sched-sp;
				phandle = <0x5b>;

				queue0 {
					snps,dcb-algorithm;
					snps,map-to-dma-channel = <0x00>;
				};

				queue1 {
					snps,dcb-algorithm;
					snps,map-to-dma-channel = <0x00>;
				};

				queue2 {
					snps,dcb-algorithm;
					snps,map-to-dma-channel = <0x00>;
				};

				queue3 {
					snps,dcb-algorithm;
					snps,map-to-dma-channel = <0x00>;
				};
			};

			tx-queues-config {
				snps,tx-queues-to-use = <0x04>;
				snps,tx-sched-wrr;
				phandle = <0x5c>;

				queue0 {
					snps,dcb-algorithm;
					snps,priority = <0x00>;
					snps,weight = <0x10>;
				};

				queue1 {
					snps,dcb-algorithm;
					snps,priority = <0x01>;
					snps,weight = <0x11>;
				};

				queue2 {
					snps,dcb-algorithm;
					snps,priority = <0x02>;
					snps,weight = <0x12>;
				};

				queue3 {
					snps,dcb-algorithm;
					snps,priority = <0x03>;
					snps,weight = <0x13>;
				};
			};
		};

		mmc@11230000 {
			compatible = "mediatek,mt8188-mmc", "mediatek,mt8183-mmc";
			reg = <0x00 0x11230000 0x00 0x10000 0x00 0x11f50000 0x00 0x1000>;
			interrupts = <0x00 0x83 0x04 0x00>;
			clocks = <0x2d 0x1b 0x2e 0x19 0x2e 0x1c 0x2e 0x4d>;
			clock-names = "source", "hclk", "source_cg", "crypto_clk";
			status = "okay";
			bus-width = <0x08>;
			cap-mmc-highspeed;
			cap-mmc-hw-reset;
			hs400-ds-delay = <0x1481b>;
			max-frequency = <0xbebc200>;
			mmc-hs200-1_8v;
			mmc-hs400-1_8v;
			mmc-hs400-enhanced-strobe;
			no-sd;
			no-sdio;
			non-removable;
			pinctrl-names = "default", "state_uhs";
			pinctrl-0 = <0x5d>;
			pinctrl-1 = <0x5e>;
			supports-cqe;
			vmmc-supply = <0x5f>;
			vqmmc-supply = <0x60>;
		};

		mmc@11240000 {
			compatible = "mediatek,mt8188-mmc", "mediatek,mt8183-mmc";
			reg = <0x00 0x11240000 0x00 0x1000 0x00 0x11eb0000 0x00 0x1000>;
			interrupts = <0x00 0x87 0x04 0x00>;
			clocks = <0x2d 0x1c 0x2e 0x1a 0x2e 0x24>;
			clock-names = "source", "hclk", "source_cg";
			assigned-clocks = <0x2d 0x1c>;
			assigned-clock-parents = <0x2d 0x9d>;
			status = "disabled";
		};

		mmc@11250000 {
			compatible = "mediatek,mt8188-mmc", "mediatek,mt8183-mmc";
			reg = <0x00 0x11250000 0x00 0x1000 0x00 0x11e60000 0x00 0x1000>;
			interrupts = <0x00 0x88 0x04 0x00>;
			clocks = <0x2d 0x1d 0x2e 0x1b 0x2e 0x41>;
			clock-names = "source", "hclk", "source_cg";
			assigned-clocks = <0x2d 0x1d>;
			assigned-clock-parents = <0x2d 0x9d>;
			status = "disabled";
		};

		thermal-sensor@11278000 {
			compatible = "mediatek,mt8188-lvts-mcu";
			reg = <0x00 0x11278000 0x00 0x1000>;
			interrupts = <0x00 0xca 0x04 0x00>;
			clocks = <0x2e 0x08>;
			resets = <0x2e 0x00>;
			nvmem-cells = <0x4f>;
			nvmem-cell-names = "lvts-calib-data-1";
			#thermal-sensor-cells = <0x01>;
			phandle = <0x1f>;
		};

		i2c@11280000 {
			compatible = "mediatek,mt8188-i2c";
			reg = <0x00 0x11280000 0x00 0x1000 0x00 0x10220080 0x00 0x80>;
			interrupts = <0x00 0x97 0x04 0x00>;
			clock-div = <0x01>;
			clocks = <0x61 0x00 0x2e 0x37>;
			clock-names = "main", "dma";
			#address-cells = <0x01>;
			#size-cells = <0x00>;
			status = "okay";
			pinctrl-names = "default";
			pinctrl-0 = <0x62>;
			clock-frequency = <0x61a80>;

			audio-codec@19 {
				compatible = "everest,es8326";
				reg = <0x19>;
				interrupts-extended = <0x2a 0x6c 0x08>;
				pinctrl-names = "default";
				pinctrl-0 = <0x63>;
				#sound-dai-cells = <0x00>;
				everest,jack-pol = [0e];
				everest,interrupt-clk = [00];
				phandle = <0x1d>;
			};

			amplifier@4f {
				compatible = "ti,tas2563", "ti,tas2781";
				reg = <0x4f 0x4c>;
				reset-gpios = <0x2a 0x76 0x00>;
				#sound-dai-cells = <0x00>;
				phandle = <0x1c>;
			};
		};

		i2c@11281000 {
			compatible = "mediatek,mt8188-i2c";
			reg = <0x00 0x11281000 0x00 0x1000 0x00 0x10220180 0x00 0x80>;
			interrupts = <0x00 0x92 0x04 0x00>;
			clock-div = <0x01>;
			clocks = <0x61 0x01 0x2e 0x37>;
			clock-names = "main", "dma";
			#address-cells = <0x01>;
			#size-cells = <0x00>;
			status = "okay";
			pinctrl-names = "default";
			pinctrl-0 = <0x64>;
			clock-frequency = <0x61a80>;
		};

		i2c@11282000 {
			compatible = "mediatek,mt8188-i2c";
			reg = <0x00 0x11282000 0x00 0x1000 0x00 0x10220280 0x00 0x80>;
			interrupts = <0x00 0x93 0x04 0x00>;
			clock-div = <0x01>;
			clocks = <0x61 0x02 0x2e 0x37>;
			clock-names = "main", "dma";
			#address-cells = <0x01>;
			#size-cells = <0x00>;
			status = "okay";
			pinctrl-names = "default";
			pinctrl-0 = <0x65>;
			clock-frequency = <0x61a80>;
		};

		clock-controller@11283000 {
			compatible = "mediatek,mt8188-imp-iic-wrap-c";
			reg = <0x00 0x11283000 0x00 0x1000>;
			#clock-cells = <0x01>;
			phandle = <0x61>;
		};

		usb@112a1000 {
			compatible = "mediatek,mt8188-mtu3", "mediatek,mtu3";
			reg = <0x00 0x112a1000 0x00 0x2dff 0x00 0x112a3e00 0x00 0x100>;
			reg-names = "mac", "ippc";
			ranges = <0x00 0x00 0x00 0x112a0000 0x00 0x3f00>;
			#address-cells = <0x02>;
			#size-cells = <0x02>;
			interrupts = <0x00 0x217 0x04 0x00>;
			assigned-clocks = <0x2d 0x2d>;
			assigned-clock-parents = <0x2d 0x76>;
			clocks = <0x3e 0x07 0x2d 0xcb 0x3e 0x08>;
			clock-names = "sys_ck", "ref_ck", "mcu_ck";
			phys = <0x66 0x03>;
			wakeup-source;
			mediatek,syscon-wakeup = <0x57 0x470 0x02>;
			status = "okay";
			dr_mode = "host";
			vusb33-supply = <0x58>;

			usb@0 {
				compatible = "mediatek,mt8188-xhci", "mediatek,mtk-xhci";
				reg = <0x00 0x00 0x00 0x1000>;
				reg-names = "mac";
				interrupts = <0x00 0x218 0x04 0x00>;
				assigned-clocks = <0x2d 0x2e>;
				assigned-clock-parents = <0x2d 0x76>;
				clocks = <0x3e 0x08>;
				clock-names = "sys_ck";
				status = "okay";
				usb2-lpm-disable;
			};
		};

		usb@112b1000 {
			compatible = "mediatek,mt8188-mtu3", "mediatek,mtu3";
			reg = <0x00 0x112b1000 0x00 0x2dff 0x00 0x112b3e00 0x00 0x100>;
			reg-names = "mac", "ippc";
			ranges = <0x00 0x00 0x00 0x112b0000 0x00 0x3f00>;
			#address-cells = <0x02>;
			#size-cells = <0x02>;
			interrupts = <0x00 0x214 0x04 0x00>;
			assigned-clocks = <0x2d 0x2c>;
			assigned-clock-parents = <0x2d 0x76>;
			clocks = <0x3e 0x05 0x2d 0xc9 0x3e 0x06>;
			clock-names = "sys_ck", "ref_ck", "mcu_ck";
			phys = <0x67 0x03>;
			wakeup-source;
			mediatek,syscon-wakeup = <0x57 0x460 0x02>;
			status = "okay";
			dr_mode = "host";
			vusb33-supply = <0x58>;

			usb@0 {
				compatible = "mediatek,mt8188-xhci", "mediatek,mtk-xhci";
				reg = <0x00 0x00 0x00 0x1000>;
				reg-names = "mac";
				interrupts = <0x00 0x215 0x04 0x00>;
				assigned-clocks = <0x2d 0x2b>;
				assigned-clock-parents = <0x2d 0x76>;
				clocks = <0x3e 0x06>;
				clock-names = "sys_ck";
				status = "okay";
				vbus-supply = <0x68>;
			};
		};

		pcie@112f0000 {
			compatible = "mediatek,mt8188-pcie", "mediatek,mt8192-pcie";
			reg = <0x00 0x112f0000 0x00 0x2000>;
			reg-names = "pcie-mac";
			ranges = <0x82000000 0x00 0x20000000 0x00 0x20000000 0x00 0x4000000>;
			bus-range = <0x00 0xff>;
			device_type = "pci";
			linux,pci-domain = <0x00>;
			#address-cells = <0x03>;
			#size-cells = <0x02>;
			clocks = <0x2e 0x4c 0x2e 0x23 0x2e 0x26 0x2e 0x2b 0x2e 0x43 0x3e 0x0c>;
			clock-names = "pl_250m", "tl_26m", "tl_96m", "tl_32k", "peri_26m", "peri_mem";
			#interrupt-cells = <0x01>;
			interrupts = <0x00 0x317 0x04 0x00>;
			interrupt-map = <0x00 0x00 0x00 0x01 0x69 0x00 0x00 0x00 0x00 0x02 0x69 0x01 0x00 0x00 0x00 0x03 0x69 0x02 0x00 0x00 0x00 0x04 0x69 0x03>;
			interrupt-map-mask = <0x00 0x00 0x00 0x07>;
			iommu-map = <0x00 0x6a 0x00 0xffff>;
			iommu-map-mask = <0x00>;
			phys = <0x6b 0x02>;
			phy-names = "pcie-phy";
			power-domains = <0x44 0x05>;
			resets = <0x45 0x13>;
			reset-names = "mac";
			vpcie3v3-supply = <0xb5>;
			status = "okay";
			pinctrl-names = "default";
			pinctrl-0 = <0x6c>;

			interrupt-controller {
				#address-cells = <0x00>;
				#interrupt-cells = <0x01>;
				interrupt-controller;
				phandle = <0x69>;
			};
		};

		spi@1132c000 {
			compatible = "mediatek,mt8188-nor", "mediatek,mt8186-nor";
			reg = <0x00 0x1132c000 0x00 0x1000>;
			clocks = <0x2d 0x58 0x3e 0x04 0x3e 0x02>;
			clock-names = "spi", "sf", "axi";
			assigned-clocks = <0x2d 0x58>;
			interrupts = <0x00 0x339 0x04 0x00>;
			#address-cells = <0x01>;
			#size-cells = <0x00>;
			status = "okay";
			pinctrl-names = "default";
			pinctrl-0 = <0x6d>;

			flash@0 {
				compatible = "jedec,spi-nor";
				reg = <0x00>;
				spi-max-frequency = <0x3197500>;
			};
		};

		t-phy@11c20700 {
			compatible = "mediatek,mt8188-tphy", "mediatek,generic-tphy-v3";
			ranges = <0x00 0x00 0x11c20700 0x700>;
			#address-cells = <0x01>;
			#size-cells = <0x01>;
			power-domains = <0x44 0x06>;
			status = "okay";

			pcie-phy@0 {
				reg = <0x00 0x700>;
				clocks = <0x2d 0xc4>;
				clock-names = "ref";
				#phy-cells = <0x01>;
				phandle = <0x6b>;
			};
		};

		dsi-phy@11c80000 {
			compatible = "mediatek,mt8188-mipi-tx", "mediatek,mt8183-mipi-tx";
			reg = <0x00 0x11c80000 0x00 0x1000>;
			clocks = <0x43>;
			clock-output-names = "mipi_tx0_pll";
			#clock-cells = <0x00>;
			#phy-cells = <0x00>;
			status = "okay";
			drive-strength-microamp = <0x1450>;
			phandle = <0x93>;
		};

		dsi-phy@11c90000 {
			compatible = "mediatek,mt8188-mipi-tx", "mediatek,mt8183-mipi-tx";
			reg = <0x00 0x11c90000 0x00 0x1000>;
			clocks = <0x43>;
			clock-output-names = "mipi_tx0_pll";
			#clock-cells = <0x00>;
			#phy-cells = <0x00>;
			status = "disabled";
			phandle = <0x9c>;
		};

		i2c@11e00000 {
			compatible = "mediatek,mt8188-i2c";
			reg = <0x00 0x11e00000 0x00 0x1000 0x00 0x10220100 0x00 0x80>;
			interrupts = <0x00 0x98 0x04 0x00>;
			clock-div = <0x01>;
			clocks = <0x6e 0x00 0x2e 0x37>;
			clock-names = "main", "dma";
			#address-cells = <0x01>;
			#size-cells = <0x00>;
			status = "okay";
			pinctrl-names = "default";
			pinctrl-0 = <0x6f>;
			clock-frequency = <0x61a80>;

			tpm@50 {
				compatible = "google,cr50";
				reg = <0x50>;
				interrupts-extended = <0x2a 0x00 0x01>;
				pinctrl-names = "default";
				pinctrl-0 = <0x70>;
			};
		};

		i2c@11e01000 {
			compatible = "mediatek,mt8188-i2c";
			reg = <0x00 0x11e01000 0x00 0x1000 0x00 0x10220380 0x00 0x80>;
			interrupts = <0x00 0x94 0x04 0x00>;
			clock-div = <0x01>;
			clocks = <0x6e 0x01 0x2e 0x37>;
			clock-names = "main", "dma";
			#address-cells = <0x01>;
			#size-cells = <0x00>;
			status = "okay";
			pinctrl-names = "default";
			pinctrl-0 = <0x71>;
			clock-frequency = <0x61a80>;
		};

		clock-controller@11e02000 {
			compatible = "mediatek,mt8188-imp-iic-wrap-w";
			reg = <0x00 0x11e02000 0x00 0x1000>;
			#clock-cells = <0x01>;
			phandle = <0x6e>;
		};

		t-phy@11e30000 {
			compatible = "mediatek,mt8188-tphy", "mediatek,generic-tphy-v3";
			#address-cells = <0x01>;
			#size-cells = <0x01>;
			ranges = <0x00 0x00 0x11e30000 0x1000>;
			status = "okay";

			usb-phy@0 {
				reg = <0x00 0x700>;
				clocks = <0x2d 0xca 0x2c 0x0f>;
				clock-names = "ref", "da_ref";
				#phy-cells = <0x01>;
				phandle = <0x67>;
			};
		};

		t-phy@11e40000 {
			compatible = "mediatek,mt8188-tphy", "mediatek,generic-tphy-v3";
			#address-cells = <0x01>;
			#size-cells = <0x01>;
			ranges = <0x00 0x00 0x11e40000 0x1000>;
			status = "okay";

			usb-phy@0 {
				reg = <0x00 0x700>;
				clocks = <0x2d 0xc6 0x2c 0x0f>;
				clock-names = "ref", "da_ref";
				#phy-cells = <0x01>;
				phandle = <0x55>;
			};

			usb-phy@700 {
				reg = <0x700 0x700>;
				clocks = <0x2c 0x0f 0x43>;
				clock-names = "ref", "da_ref";
				#phy-cells = <0x01>;
				phandle = <0x56>;
			};
		};

		t-phy@11e80000 {
			compatible = "mediatek,mt8188-tphy", "mediatek,generic-tphy-v3";
			#address-cells = <0x01>;
			#size-cells = <0x01>;
			ranges = <0x00 0x00 0x11e80000 0x1000>;
			status = "okay";

			usb-phy@0 {
				reg = <0x00 0x700>;
				clocks = <0x2d 0xcc 0x2c 0x0f>;
				clock-names = "ref", "da_ref";
				#phy-cells = <0x01>;
				phandle = <0x66>;
			};
		};

		i2c@11ec0000 {
			compatible = "mediatek,mt8188-i2c";
			reg = <0x00 0x11ec0000 0x00 0x1000 0x00 0x10220480 0x00 0x80>;
			interrupts = <0x00 0x95 0x04 0x00>;
			clock-div = <0x01>;
			clocks = <0x72 0x00 0x2e 0x37>;
			clock-names = "main", "dma";
			#address-cells = <0x01>;
			#size-cells = <0x00>;
			status = "okay";
			pinctrl-names = "default";
			pinctrl-0 = <0x73>;
			clock-frequency = <0x61a80>;
		};

		i2c@11ec1000 {
			compatible = "mediatek,mt8188-i2c";
			reg = <0x00 0x11ec1000 0x00 0x1000 0x00 0x10220600 0x00 0x80>;
			interrupts = <0x00 0x96 0x04 0x00>;
			clock-div = <0x01>;
			clocks = <0x72 0x01 0x2e 0x37>;
			clock-names = "main", "dma";
			#address-cells = <0x01>;
			#size-cells = <0x00>;
			status = "okay";
			pinctrl-names = "default";
			pinctrl-0 = <0x74>;
			clock-frequency = <0x61a80>;
		};

		clock-controller@11ec2000 {
			compatible = "mediatek,mt8188-imp-iic-wrap-en";
			reg = <0x00 0x11ec2000 0x00 0x1000>;
			#clock-cells = <0x01>;
			phandle = <0x72>;
		};

		efuse@11f20000 {
			compatible = "mediatek,mt8188-efuse", "mediatek,mt8186-efuse";
			reg = <0x00 0x11f20000 0x00 0x1000>;
			#address-cells = <0x01>;
			#size-cells = <0x01>;

			dp-calib@1a0 {
				reg = <0x1a0 0x0c>;
				phandle = <0xac>;
			};

			lvts1-calib@1ac {
				reg = <0x1ac 0x40>;
				phandle = <0x4f>;
			};

			gpu-speedbin@581 {
				reg = <0x581 0x01>;
				bits = <0x00 0x03>;
				phandle = <0x76>;
			};

			socinfo-data1@7a0 {
				reg = <0x7a0 0x04>;
			};

			socinfo-data2@7e0 {
				reg = <0x7e0 0x04>;
			};
		};

		gpu@13000000 {
			compatible = "mediatek,mt8188-mali", "arm,mali-valhall-jm";
			reg = <0x00 0x13000000 0x00 0x4000>;
			clocks = <0x75 0x00>;
			interrupts = <0x00 0x17f 0x04 0x00 0x00 0x17e 0x04 0x00 0x00 0x17d 0x04 0x00>;
			interrupt-names = "job", "mmu", "gpu";
			nvmem-cells = <0x76>;
			nvmem-cell-names = "speed-bin";
			operating-points-v2 = <0x77>;
			power-domains = <0x44 0x02 0x44 0x03 0x44 0x04>;
			power-domain-names = "core0", "core1", "core2";
			#cooling-cells = <0x02>;
			status = "okay";
			mali-supply = <0x2b>;
			phandle = <0x28>;
		};

		clock-controller@13fbf000 {
			compatible = "mediatek,mt8188-mfgcfg";
			reg = <0x00 0x13fbf000 0x00 0x1000>;
			#clock-cells = <0x01>;
			phandle = <0x75>;
		};

		syscon@14000000 {
			compatible = "mediatek,mt8188-vppsys0", "syscon";
			reg = <0x00 0x14000000 0x00 0x1000>;
			#clock-cells = <0x01>;
			phandle = <0x30>;
		};

		dma-controller@14001000 {
			compatible = "mediatek,mt8188-mdp3-rdma";
			reg = <0x00 0x14001000 0x00 0x1000>;
			#dma-cells = <0x01>;
			clocks = <0x30 0x18>;
			mboxes = <0x78 0x0d 0x01 0x78 0x0e 0x01 0x78 0x10 0x01 0x78 0x15 0x01 0x78 0x16 0x01>;
			iommus = <0x79 0x80>;
			power-domains = <0x44 0x0f>;
			mediatek,gce-client-reg = <0x7a 0x00 0x1000 0x1000>;
			mediatek,gce-events = <0x100 0x120>;
			mediatek,scp = <0x7b>;
		};

		display@14002000 {
			compatible = "mediatek,mt8188-mdp3-fg", "mediatek,mt8195-mdp3-fg";
			reg = <0x00 0x14002000 0x00 0x1000>;
			clocks = <0x30 0x00>;
			mediatek,gce-client-reg = <0x7a 0x00 0x2000 0x1000>;
		};

		display@14004000 {
			compatible = "mediatek,mt8188-mdp3-hdr", "mediatek,mt8195-mdp3-hdr";
			reg = <0x00 0x14004000 0x00 0x1000>;
			clocks = <0x30 0x22>;
			mediatek,gce-client-reg = <0x7a 0x00 0x4000 0x1000>;
		};

		display@14005000 {
			compatible = "mediatek,mt8188-mdp3-aal", "mediatek,mt8195-mdp3-aal";
			reg = <0x00 0x14005000 0x00 0x1000>;
			interrupts = <0x00 0x246 0x04 0x00>;
			clocks = <0x30 0x0a>;
			power-domains = <0x44 0x0f>;
			mediatek,gce-client-reg = <0x7a 0x00 0x5000 0x1000>;
		};

		display@14006000 {
			compatible = "mediatek,mt8188-mdp3-rsz", "mediatek,mt8183-mdp3-rsz";
			reg = <0x00 0x14006000 0x00 0x1000>;
			clocks = <0x30 0x0b>;
			mediatek,gce-client-reg = <0x7a 0x00 0x6000 0x1000>;
			mediatek,gce-events = <0x105 0x125>;
		};

		display@14007000 {
			compatible = "mediatek,mt8188-mdp3-tdshp", "mediatek,mt8195-mdp3-tdshp";
			reg = <0x00 0x14007000 0x00 0x1000>;
			clocks = <0x30 0x23>;
			mediatek,gce-client-reg = <0x7a 0x00 0x7000 0x1000>;
		};

		display@14008000 {
			compatible = "mediatek,mt8188-mdp3-color", "mediatek,mt8195-mdp3-color";
			reg = <0x00 0x14008000 0x00 0x1000>;
			interrupts = <0x00 0x249 0x04 0x00>;
			clocks = <0x30 0x24>;
			power-domains = <0x44 0x0f>;
			mediatek,gce-client-reg = <0x7a 0x00 0x8000 0x1000>;
		};

		display@14009000 {
			compatible = "mediatek,mt8188-mdp3-ovl", "mediatek,mt8195-mdp3-ovl";
			reg = <0x00 0x14009000 0x00 0x1000>;
			interrupts = <0x00 0x24a 0x04 0x00>;
			clocks = <0x30 0x25>;
			power-domains = <0x44 0x0f>;
			mediatek,gce-client-reg = <0x7a 0x00 0x9000 0x1000>;
			iommus = <0x79 0x82>;
		};

		display@1400a000 {
			compatible = "mediatek,mt8188-mdp3-padding", "mediatek,mt8195-mdp3-padding";
			reg = <0x00 0x1400a000 0x00 0x1000>;
			clocks = <0x30 0x02>;
			power-domains = <0x44 0x0f>;
			mediatek,gce-client-reg = <0x7a 0x00 0xa000 0x1000>;
		};

		display@1400b000 {
			compatible = "mediatek,mt8188-mdp3-tcc", "mediatek,mt8195-mdp3-tcc";
			reg = <0x00 0x1400b000 0x00 0x1000>;
			clocks = <0x30 0x03>;
			mediatek,gce-client-reg = <0x7a 0x00 0xb000 0x1000>;
		};

		display@1400c000 {
			compatible = "mediatek,mt8188-mdp3-wrot", "mediatek,mt8183-mdp3-wrot";
			reg = <0x00 0x1400c000 0x00 0x1000>;
			#dma-cells = <0x01>;
			clocks = <0x30 0x19>;
			iommus = <0x79 0x83>;
			power-domains = <0x44 0x0f>;
			mediatek,gce-client-reg = <0x7a 0x00 0xc000 0x1000>;
			mediatek,gce-events = <0x10b 0x12b>;
		};

		mutex@1400f000 {
			compatible = "mediatek,mt8188-vpp-mutex";
			reg = <0x00 0x1400f000 0x00 0x1000>;
			interrupts = <0x00 0x250 0x04 0x00>;
			clocks = <0x30 0x06>;
			power-domains = <0x44 0x0f>;
			mediatek,gce-client-reg = <0x7a 0x00 0xf000 0x1000>;
		};

		smi@14012000 {
			compatible = "mediatek,mt8188-smi-common-vpp";
			reg = <0x00 0x14012000 0x00 0x1000>;
			clocks = <0x30 0x1d 0x30 0x1b>;
			clock-names = "apb", "smi";
			power-domains = <0x44 0x0f>;
			phandle = <0x7c>;
		};

		smi@14013000 {
			compatible = "mediatek,mt8188-smi-larb";
			reg = <0x00 0x14013000 0x00 0x1000>;
			clocks = <0x30 0x1d 0x30 0x1d>;
			clock-names = "apb", "smi";
			power-domains = <0x44 0x0f>;
			mediatek,larb-id = <0x04>;
			mediatek,smi = <0x7c>;
			phandle = <0x7f>;
		};

		iommu@14018000 {
			compatible = "mediatek,mt8188-iommu-vpp";
			reg = <0x00 0x14018000 0x00 0x5000>;
			clocks = <0x30 0x16>;
			clock-names = "bclk";
			interrupts = <0x00 0x252 0x04 0x00>;
			power-domains = <0x44 0x0f>;
			#iommu-cells = <0x01>;
			mediatek,larbs = <0x7d 0x7e 0x7f 0x80 0x81 0x82>;
			phandle = <0x79>;
		};

		dma-controller@14f09000 {
			compatible = "mediatek,mt8188-mdp3-rdma";
			reg = <0x00 0x14f09000 0x00 0x1000>;
			#dma-cells = <0x01>;
			clocks = <0x32 0x0a>;
			iommus = <0x83 0xa4>;
			power-domains = <0x44 0x14>;
			mediatek,gce-client-reg = <0x7a 0x09 0x9000 0x1000>;
			mediatek,gce-events = <0x185 0x1a9>;
		};

		dma-controller@14f0a000 {
			compatible = "mediatek,mt8188-mdp3-rdma";
			reg = <0x00 0x14f0a000 0x00 0x1000>;
			#dma-cells = <0x01>;
			clocks = <0x32 0x0c>;
			iommus = <0x79 0xc0>;
			power-domains = <0x44 0x14>;
			mediatek,gce-client-reg = <0x7a 0x09 0xa000 0x1000>;
			mediatek,gce-events = <0x186 0x1aa>;
		};

		display@14f0c000 {
			compatible = "mediatek,mt8188-mdp3-fg", "mediatek,mt8195-mdp3-fg";
			reg = <0x00 0x14f0c000 0x00 0x1000>;
			clocks = <0x32 0x0b>;
			mediatek,gce-client-reg = <0x7a 0x09 0xc000 0x1000>;
		};

		display@14f0d000 {
			compatible = "mediatek,mt8188-mdp3-fg", "mediatek,mt8195-mdp3-fg";
			reg = <0x00 0x14f0d000 0x00 0x1000>;
			clocks = <0x32 0x0d>;
			mediatek,gce-client-reg = <0x7a 0x09 0xd000 0x1000>;
		};

		display@14f0f000 {
			compatible = "mediatek,mt8188-mdp3-hdr", "mediatek,mt8195-mdp3-hdr";
			reg = <0x00 0x14f0f000 0x00 0x1000>;
			clocks = <0x32 0x22>;
			mediatek,gce-client-reg = <0x7a 0x09 0xf000 0x1000>;
		};

		display@14f10000 {
			compatible = "mediatek,mt8188-mdp3-hdr", "mediatek,mt8195-mdp3-hdr";
			reg = <0x00 0x14f10000 0x00 0x1000>;
			clocks = <0x32 0x24>;
			mediatek,gce-client-reg = <0x7a 0x0a 0x00 0x1000>;
		};

		display@14f12000 {
			compatible = "mediatek,mt8188-mdp3-aal", "mediatek,mt8195-mdp3-aal";
			reg = <0x00 0x14f12000 0x00 0x1000>;
			interrupts = <0x00 0x26a 0x04 0x00>;
			clocks = <0x32 0x23>;
			power-domains = <0x44 0x14>;
			mediatek,gce-client-reg = <0x7a 0x0a 0x2000 0x1000>;
		};

		display@14f13000 {
			compatible = "mediatek,mt8188-mdp3-aal", "mediatek,mt8195-mdp3-aal";
			reg = <0x00 0x14f13000 0x00 0x1000>;
			interrupts = <0x00 0x26b 0x04 0x00>;
			clocks = <0x32 0x25>;
			power-domains = <0x44 0x14>;
			mediatek,gce-client-reg = <0x7a 0x0a 0x3000 0x1000>;
		};

		display@14f15000 {
			compatible = "mediatek,mt8188-mdp3-rsz", "mediatek,mt8183-mdp3-rsz";
			reg = <0x00 0x14f15000 0x00 0x1000>;
			clocks = <0x32 0x14>;
			mediatek,gce-client-reg = <0x7a 0x0a 0x5000 0x1000>;
			mediatek,gce-events = <0x191 0x1b0>;
		};

		display@14f16000 {
			compatible = "mediatek,mt8188-mdp3-rsz", "mediatek,mt8183-mdp3-rsz";
			reg = <0x00 0x14f16000 0x00 0x1000>;
			clocks = <0x32 0x18>;
			mediatek,gce-client-reg = <0x7a 0x0a 0x6000 0x1000>;
			mediatek,gce-events = <0x192 0x1b1>;
		};

		display@14f18000 {
			compatible = "mediatek,mt8188-mdp3-tdshp", "mediatek,mt8195-mdp3-tdshp";
			reg = <0x00 0x14f18000 0x00 0x1000>;
			clocks = <0x32 0x16>;
			mediatek,gce-client-reg = <0x7a 0x0a 0x8000 0x1000>;
		};

		display@14f19000 {
			compatible = "mediatek,mt8188-mdp3-tdshp", "mediatek,mt8195-mdp3-tdshp";
			reg = <0x00 0x14f19000 0x00 0x1000>;
			clocks = <0x32 0x1a>;
			mediatek,gce-client-reg = <0x7a 0x0a 0x9000 0x1000>;
		};

		display@14f1a000 {
			compatible = "mediatek,mt8188-mdp3-merge", "mediatek,mt8195-mdp3-merge";
			reg = <0x00 0x14f1a000 0x00 0x1000>;
			clocks = <0x32 0x15>;
			power-domains = <0x44 0x14>;
			mediatek,gce-client-reg = <0x7a 0x0a 0xa000 0x1000>;
		};

		display@14f1b000 {
			compatible = "mediatek,mt8188-mdp3-merge", "mediatek,mt8195-mdp3-merge";
			reg = <0x00 0x14f1b000 0x00 0x1000>;
			clocks = <0x32 0x19>;
			power-domains = <0x44 0x14>;
			mediatek,gce-client-reg = <0x7a 0x0a 0xb000 0x1000>;
		};

		display@14f1d000 {
			compatible = "mediatek,mt8188-mdp3-color", "mediatek,mt8195-mdp3-color";
			reg = <0x00 0x14f1d000 0x00 0x1000>;
			interrupts = <0x00 0x275 0x04 0x00>;
			clocks = <0x32 0x17>;
			power-domains = <0x44 0x14>;
			mediatek,gce-client-reg = <0x7a 0x0a 0xd000 0x1000>;
		};

		display@14f1e000 {
			compatible = "mediatek,mt8188-mdp3-color", "mediatek,mt8195-mdp3-color";
			reg = <0x00 0x14f1e000 0x00 0x1000>;
			interrupts = <0x00 0x276 0x04 0x00>;
			clocks = <0x32 0x1b>;
			power-domains = <0x44 0x14>;
			mediatek,gce-client-reg = <0x7a 0x0a 0xe000 0x1000>;
		};

		display@14f21000 {
			compatible = "mediatek,mt8188-mdp3-padding", "mediatek,mt8195-mdp3-padding";
			reg = <0x00 0x14f21000 0x00 0x1000>;
			clocks = <0x32 0x05>;
			power-domains = <0x44 0x14>;
			mediatek,gce-client-reg = <0x7a 0x0b 0x1000 0x1000>;
		};

		display@14f22000 {
			compatible = "mediatek,mt8188-mdp3-padding", "mediatek,mt8195-mdp3-padding";
			reg = <0x00 0x14f22000 0x00 0x1000>;
			clocks = <0x32 0x07>;
			power-domains = <0x44 0x14>;
			mediatek,gce-client-reg = <0x7a 0x0b 0x2000 0x1000>;
		};

		display@14f24000 {
			compatible = "mediatek,mt8188-mdp3-wrot", "mediatek,mt8183-mdp3-wrot";
			reg = <0x00 0x14f24000 0x00 0x1000>;
			#dma-cells = <0x01>;
			clocks = <0x32 0x04>;
			iommus = <0x83 0xa6>;
			power-domains = <0x44 0x14>;
			mediatek,gce-client-reg = <0x7a 0x0b 0x4000 0x1000>;
			mediatek,gce-events = <0x1a0 0x1ac>;
		};

		display@14f25000 {
			compatible = "mediatek,mt8188-mdp3-wrot", "mediatek,mt8183-mdp3-wrot";
			reg = <0x00 0x14f25000 0x00 0x1000>;
			#dma-cells = <0x01>;
			clocks = <0x32 0x06>;
			iommus = <0x79 0xc2>;
			power-domains = <0x44 0x14>;
			mediatek,gce-client-reg = <0x7a 0x0b 0x5000 0x1000>;
			mediatek,gce-events = <0x1a1 0x1ad>;
		};

		clock-controller@14e00000 {
			compatible = "mediatek,mt8188-wpesys";
			reg = <0x00 0x14e00000 0x00 0x1000>;
			#clock-cells = <0x01>;
			phandle = <0x3d>;
		};

		clock-controller@14e02000 {
			compatible = "mediatek,mt8188-wpesys-vpp0";
			reg = <0x00 0x14e02000 0x00 0x1000>;
			#clock-cells = <0x01>;
		};

		smi@14e04000 {
			compatible = "mediatek,mt8188-smi-larb";
			reg = <0x00 0x14e04000 0x00 0x1000>;
			clocks = <0x3d 0x01 0x3d 0x01>;
			clock-names = "apb", "smi";
			power-domains = <0x44 0x15>;
			mediatek,larb-id = <0x07>;
			mediatek,smi = <0x7c>;
			phandle = <0x81>;
		};

		syscon@14f00000 {
			compatible = "mediatek,mt8188-vppsys1", "syscon";
			reg = <0x00 0x14f00000 0x00 0x1000>;
			#clock-cells = <0x01>;
			phandle = <0x32>;
		};

		mutex@14f01000 {
			compatible = "mediatek,mt8188-vpp-mutex";
			reg = <0x00 0x14f01000 0x00 0x1000>;
			interrupts = <0x00 0x27b 0x04 0x00>;
			clocks = <0x32 0x26>;
			power-domains = <0x44 0x14>;
			mediatek,gce-client-reg = <0x7a 0x09 0x1000 0x1000>;
		};

		smi@14f02000 {
			compatible = "mediatek,mt8188-smi-larb";
			reg = <0x00 0x14f02000 0x00 0x1000>;
			clocks = <0x32 0x1c 0x32 0x1e>;
			clock-names = "apb", "smi";
			power-domains = <0x44 0x14>;
			mediatek,larb-id = <0x05>;
			mediatek,smi = <0x84>;
			phandle = <0xa2>;
		};

		smi@14f03000 {
			compatible = "mediatek,mt8188-smi-larb";
			reg = <0x00 0x14f03000 0x00 0x1000>;
			clocks = <0x32 0x1d 0x32 0x1f>;
			clock-names = "apb", "smi";
			power-domains = <0x44 0x14>;
			mediatek,larb-id = <0x06>;
			mediatek,smi = <0x7c>;
			phandle = <0x80>;
		};

		clock-controller@15000000 {
			compatible = "mediatek,mt8188-imgsys";
			reg = <0x00 0x15000000 0x00 0x1000>;
			#clock-cells = <0x01>;
		};

		clock-controller@15110000 {
			compatible = "mediatek,mt8188-imgsys1-dip-top";
			reg = <0x00 0x15110000 0x00 0x1000>;
			#clock-cells = <0x01>;
			#reset-cells = <0x01>;
		};

		clock-controller@15130000 {
			compatible = "mediatek,mt8188-imgsys1-dip-nr";
			reg = <0x00 0x15130000 0x00 0x1000>;
			#clock-cells = <0x01>;
			#reset-cells = <0x01>;
		};

		clock-controller@15220000 {
			compatible = "mediatek,mt8188-imgsys-wpe1";
			reg = <0x00 0x15220000 0x00 0x1000>;
			#clock-cells = <0x01>;
			#reset-cells = <0x01>;
		};

		clock-controller@15330000 {
			compatible = "mediatek,mt8188-ipesys";
			reg = <0x00 0x15330000 0x00 0x1000>;
			#clock-cells = <0x01>;
			#reset-cells = <0x01>;
		};

		clock-controller@15520000 {
			compatible = "mediatek,mt8188-imgsys-wpe2";
			reg = <0x00 0x15520000 0x00 0x1000>;
			#clock-cells = <0x01>;
			#reset-cells = <0x01>;
		};

		clock-controller@15620000 {
			compatible = "mediatek,mt8188-imgsys-wpe3";
			reg = <0x00 0x15620000 0x00 0x1000>;
			#clock-cells = <0x01>;
			#reset-cells = <0x01>;
		};

		clock-controller@16000000 {
			compatible = "mediatek,mt8188-camsys";
			reg = <0x00 0x16000000 0x00 0x1000>;
			#clock-cells = <0x01>;
			phandle = <0x36>;
		};

		clock-controller@1604f000 {
			compatible = "mediatek,mt8188-camsys-rawa";
			reg = <0x00 0x1604f000 0x00 0x1000>;
			#clock-cells = <0x01>;
			#reset-cells = <0x01>;
			phandle = <0x39>;
		};

		clock-controller@1606f000 {
			compatible = "mediatek,mt8188-camsys-yuva";
			reg = <0x00 0x1606f000 0x00 0x1000>;
			#clock-cells = <0x01>;
			#reset-cells = <0x01>;
			phandle = <0x3a>;
		};

		clock-controller@1608f000 {
			compatible = "mediatek,mt8188-camsys-rawb";
			reg = <0x00 0x1608f000 0x00 0x1000>;
			#clock-cells = <0x01>;
			#reset-cells = <0x01>;
			phandle = <0x37>;
		};

		clock-controller@160af000 {
			compatible = "mediatek,mt8188-camsys-yuvb";
			reg = <0x00 0x160af000 0x00 0x1000>;
			#clock-cells = <0x01>;
			#reset-cells = <0x01>;
			phandle = <0x38>;
		};

		clock-controller@17200000 {
			compatible = "mediatek,mt8188-ccusys";
			reg = <0x00 0x17200000 0x00 0x1000>;
			#clock-cells = <0x01>;
		};

		video-decoder@18000000 {
			compatible = "mediatek,mt8188-vcodec-dec";
			reg = <0x00 0x18000000 0x00 0x1000 0x00 0x18004000 0x00 0x1000>;
			ranges = <0x00 0x00 0x00 0x18000000 0x00 0x26000>;
			iommus = <0x79 0x2e6>;
			#address-cells = <0x02>;
			#size-cells = <0x02>;
			mediatek,scp = <0x7b>;

			video-codec@10000 {
				compatible = "mediatek,mtk-vcodec-lat";
				reg = <0x00 0x10000 0x00 0x800>;
				assigned-clocks = <0x2d 0x34>;
				assigned-clock-parents = <0x2d 0x78>;
				clocks = <0x2d 0x34 0x33 0x04 0x33 0x01 0x2d 0x78>;
				clock-names = "sel", "vdec", "lat", "top";
				interrupts = <0x00 0x2c4 0x04 0x00>;
				iommus = <0x79 0x2e0 0x79 0x2e1 0x79 0x2e2 0x79 0x2e3 0x79 0x2e4 0x79 0x2e5 0x79 0x2e6 0x79 0x2e7 0x79 0x2e8>;
				power-domains = <0x44 0x16>;
			};

			video-codec@25000 {
				compatible = "mediatek,mtk-vcodec-core";
				reg = <0x00 0x25000 0x00 0x1000>;
				assigned-clocks = <0x2d 0x34>;
				assigned-clock-parents = <0x2d 0x78>;
				clocks = <0x2d 0x34 0x34 0x02 0x34 0x01 0x2d 0x78>;
				clock-names = "sel", "vdec", "lat", "top";
				interrupts = <0x00 0x2c3 0x04 0x00>;
				iommus = <0x83 0x2c0 0x83 0x2c1 0x83 0x2c2 0x83 0x2c3 0x83 0x2c4 0x83 0x2c5 0x83 0x2c6 0x83 0x2c7 0x83 0x2c8 0x83 0x2c9 0x83 0x2ca>;
				power-domains = <0x44 0x17>;
			};
		};

		smi@1800d000 {
			compatible = "mediatek,mt8188-smi-larb";
			reg = <0x00 0x1800d000 0x00 0x1000>;
			clocks = <0x33 0x00 0x33 0x00>;
			clock-names = "apb", "smi";
			power-domains = <0x44 0x16>;
			mediatek,larb-id = <0x17>;
			mediatek,smi = <0x7c>;
			phandle = <0x82>;
		};

		clock-controller@1800f000 {
			compatible = "mediatek,mt8188-vdecsys-soc";
			reg = <0x00 0x1800f000 0x00 0x1000>;
			#clock-cells = <0x01>;
			phandle = <0x33>;
		};

		smi@1802e000 {
			compatible = "mediatek,mt8188-smi-larb";
			reg = <0x00 0x1802e000 0x00 0x1000>;
			clocks = <0x34 0x00 0x34 0x00>;
			clock-names = "apb", "smi";
			power-domains = <0x44 0x17>;
			mediatek,larb-id = <0x16>;
			mediatek,smi = <0x84>;
			phandle = <0xa4>;
		};

		clock-controller@1802f000 {
			compatible = "mediatek,mt8188-vdecsys";
			reg = <0x00 0x1802f000 0x00 0x1000>;
			#clock-cells = <0x01>;
			phandle = <0x34>;
		};

		clock-controller@1a000000 {
			compatible = "mediatek,mt8188-vencsys";
			reg = <0x00 0x1a000000 0x00 0x1000>;
			#clock-cells = <0x01>;
			phandle = <0x3c>;
		};

		smi@1a010000 {
			compatible = "mediatek,mt8188-smi-larb";
			reg = <0x00 0x1a010000 0x00 0x1000>;
			clocks = <0x3c 0x01 0x3c 0x01>;
			clock-names = "apb", "smi";
			power-domains = <0x44 0x18>;
			mediatek,larb-id = <0x15>;
			mediatek,smi = <0x84>;
			phandle = <0xa3>;
		};

		video-encoder@1a020000 {
			compatible = "mediatek,mt8188-vcodec-enc";
			reg = <0x00 0x1a020000 0x00 0x10000>;
			#address-cells = <0x02>;
			#size-cells = <0x02>;
			assigned-clocks = <0x2d 0x33>;
			assigned-clock-parents = <0x2d 0x70>;
			clocks = <0x3c 0x01>;
			clock-names = "venc_sel";
			interrupts = <0x00 0x161 0x04 0x00>;
			iommus = <0x83 0x2a0 0x83 0x2a1 0x83 0x2a2 0x83 0x2a3 0x83 0x2a4 0x83 0x2b6 0x83 0x2b7 0x83 0x2b8 0x83 0x2b9 0x83 0x2aa 0x83 0x2ba>;
			power-domains = <0x44 0x18>;
			mediatek,scp = <0x7b>;
		};

		jpeg-encoder@1a030000 {
			compatible = "mediatek,mt8188-jpgenc", "mediatek,mtk-jpgenc";
			reg = <0x00 0x1a030000 0x00 0x10000>;
			clocks = <0x3c 0x02>;
			clock-names = "jpgenc";
			interrupts = <0x00 0x162 0x04 0x00>;
			iommus = <0x83 0x2a7 0x83 0x2a8 0x83 0x2a9 0x83 0x2ac>;
			power-domains = <0x44 0x18>;
		};

		jpeg-decoder@1a040000 {
			compatible = "mediatek,mt8188-jpgdec", "mediatek,mt2701-jpgdec";
			reg = <0x00 0x1a040000 0x00 0x10000>;
			clocks = <0x3c 0x00 0x3c 0x03>;
			clock-names = "jpgdec-smi", "jpgdec";
			interrupts = <0x00 0x163 0x04 0x00>;
			iommus = <0x83 0x2ad 0x83 0x2ae 0x83 0x2b2 0x83 0x2b3 0x83 0x2b4 0x83 0x2b5>;
			power-domains = <0x44 0x16>;
		};

		ovl@1c000000 {
			compatible = "mediatek,mt8188-disp-ovl", "mediatek,mt8195-disp-ovl";
			reg = <0x00 0x1c000000 0x00 0x1000>;
			clocks = <0x31 0x00>;
			interrupts = <0x00 0x27c 0x04 0x00>;
			iommus = <0x83 0x02>;
			power-domains = <0x44 0x10>;
			mediatek,gce-client-reg = <0x78 0x03 0x00 0x1000>;

			ports {
				#address-cells = <0x01>;
				#size-cells = <0x00>;

				port@0 {
					reg = <0x00>;

					endpoint {
						remote-endpoint = <0x85>;
						phandle = <0x9f>;
					};
				};

				port@1 {
					reg = <0x01>;

					endpoint {
						remote-endpoint = <0x86>;
						phandle = <0x87>;
					};
				};
			};
		};

		rdma@1c002000 {
			compatible = "mediatek,mt8188-disp-rdma", "mediatek,mt8195-disp-rdma";
			reg = <0x00 0x1c002000 0x00 0x1000>;
			clocks = <0x31 0x07>;
			interrupts = <0x00 0x27e 0x04 0x00>;
			iommus = <0x79 0x20>;
			power-domains = <0x44 0x10>;
			mediatek,gce-client-reg = <0x78 0x03 0x2000 0x1000>;

			ports {
				#address-cells = <0x01>;
				#size-cells = <0x00>;

				port@0 {
					reg = <0x00>;

					endpoint {
						remote-endpoint = <0x87>;
						phandle = <0x86>;
					};
				};

				port@1 {
					reg = <0x01>;

					endpoint {
						remote-endpoint = <0x88>;
						phandle = <0x89>;
					};
				};
			};
		};

		color@1c003000 {
			compatible = "mediatek,mt8188-disp-color", "mediatek,mt8173-disp-color";
			reg = <0x00 0x1c003000 0x00 0x1000>;
			clocks = <0x31 0x10>;
			interrupts = <0x00 0x27f 0x04 0x00>;
			power-domains = <0x44 0x10>;
			mediatek,gce-client-reg = <0x78 0x03 0x3000 0x1000>;

			ports {
				#address-cells = <0x01>;
				#size-cells = <0x00>;

				port@0 {
					reg = <0x00>;

					endpoint {
						remote-endpoint = <0x89>;
						phandle = <0x88>;
					};
				};

				port@1 {
					reg = <0x01>;

					endpoint {
						remote-endpoint = <0x8a>;
						phandle = <0x8b>;
					};
				};
			};
		};

		ccorr@1c004000 {
			compatible = "mediatek,mt8188-disp-ccorr", "mediatek,mt8192-disp-ccorr";
			reg = <0x00 0x1c004000 0x00 0x1000>;
			clocks = <0x31 0x02>;
			interrupts = <0x00 0x280 0x04 0x00>;
			power-domains = <0x44 0x10>;
			mediatek,gce-client-reg = <0x78 0x03 0x4000 0x1000>;

			ports {
				#address-cells = <0x01>;
				#size-cells = <0x00>;

				port@0 {
					reg = <0x00>;

					endpoint {
						remote-endpoint = <0x8b>;
						phandle = <0x8a>;
					};
				};

				port@1 {
					reg = <0x01>;

					endpoint {
						remote-endpoint = <0x8c>;
						phandle = <0x8d>;
					};
				};
			};
		};

		aal@1c005000 {
			compatible = "mediatek,mt8188-disp-aal", "mediatek,mt8183-disp-aal";
			reg = <0x00 0x1c005000 0x00 0x1000>;
			clocks = <0x31 0x0d>;
			interrupts = <0x00 0x281 0x04 0x00>;
			power-domains = <0x44 0x10>;
			mediatek,gce-client-reg = <0x78 0x03 0x5000 0x1000>;

			ports {
				#address-cells = <0x01>;
				#size-cells = <0x00>;

				port@0 {
					reg = <0x00>;

					endpoint {
						remote-endpoint = <0x8d>;
						phandle = <0x8c>;
					};
				};

				port@1 {
					reg = <0x01>;

					endpoint {
						remote-endpoint = <0x8e>;
						phandle = <0x8f>;
					};
				};
			};
		};

		gamma@1c006000 {
			compatible = "mediatek,mt8188-disp-gamma", "mediatek,mt8195-disp-gamma";
			reg = <0x00 0x1c006000 0x00 0x1000>;
			clocks = <0x31 0x04>;
			interrupts = <0x00 0x282 0x04 0x00>;
			power-domains = <0x44 0x10>;
			mediatek,gce-client-reg = <0x78 0x03 0x6000 0x1000>;

			ports {
				#address-cells = <0x01>;
				#size-cells = <0x00>;

				port@0 {
					reg = <0x00>;

					endpoint {
						remote-endpoint = <0x8f>;
						phandle = <0x8e>;
					};
				};

				port@1 {
					reg = <0x01>;

					endpoint {
						remote-endpoint = <0x90>;
						phandle = <0x9d>;
					};
				};
			};
		};

		dither@1c007000 {
			compatible = "mediatek,mt8188-disp-dither", "mediatek,mt8183-disp-dither";
			reg = <0x00 0x1c007000 0x00 0x1000>;
			clocks = <0x31 0x05>;
			interrupts = <0x00 0x283 0x04 0x00>;
			power-domains = <0x44 0x10>;
			mediatek,gce-client-reg = <0x78 0x03 0x7000 0x1000>;

			ports {
				#address-cells = <0x01>;
				#size-cells = <0x00>;

				port@0 {
					reg = <0x00>;

					endpoint {
						remote-endpoint = <0x91>;
						phandle = <0x9e>;
					};
				};

				port@1 {
					reg = <0x01>;

					endpoint {
						remote-endpoint = <0x92>;
						phandle = <0x9a>;
					};
				};
			};
		};

		dsi@1c008000 {
			compatible = "mediatek,mt8188-dsi";
			reg = <0x00 0x1c008000 0x00 0x1000>;
			clocks = <0x31 0x08 0x31 0x1e 0x93>;
			clock-names = "engine", "digital", "hs";
			interrupts = <0x00 0x284 0x04 0x00>;
			phys = <0x93>;
			phy-names = "dphy";
			power-domains = <0x44 0x10>;
			resets = <0x31 0x08>;
			status = "okay";
			#address-cells = <0x01>;
			#size-cells = <0x00>;

			panel@0 {
				reg = <0x00>;
				enable-gpios = <0x2a 0x19 0x00>;
				pinctrl-names = "default";
				pinctrl-0 = <0x94>;
				backlight = <0x95>;
				avdd-supply = <0x96>;
				avee-supply = <0x97>;
				pp1800-supply = <0x98>;
				rotation = <0x10e>;
				status = "okay";
				compatible = "boe,nv110wum-l60", "himax,hx83102";

				port {

					endpoint {
						remote-endpoint = <0x99>;
						phandle = <0x9b>;
					};
				};
			};

			ports {
				#address-cells = <0x01>;
				#size-cells = <0x00>;

				port@0 {
					reg = <0x00>;

					endpoint {
						remote-endpoint = <0x9a>;
						phandle = <0x92>;
					};
				};

				port@1 {
					reg = <0x01>;

					endpoint {
						remote-endpoint = <0x9b>;
						phandle = <0x99>;
					};
				};
			};
		};

		dsc@1c009000 {
			compatible = "mediatek,mt8188-disp-dsc", "mediatek,mt8195-disp-dsc";
			reg = <0x00 0x1c009000 0x00 0x1000>;
			clocks = <0x31 0x0a>;
			interrupts = <0x00 0x285 0x04 0x00>;
			power-domains = <0x44 0x10>;
			mediatek,gce-client-reg = <0x78 0x03 0x9000 0x1000>;
		};

		dsi@1c012000 {
			compatible = "mediatek,mt8188-dsi";
			reg = <0x00 0x1c012000 0x00 0x1000>;
			clocks = <0x31 0x09 0x31 0x1f 0x9c>;
			clock-names = "engine", "digital", "hs";
			interrupts = <0x00 0x28e 0x04 0x00>;
			phys = <0x9c>;
			phy-names = "dphy";
			power-domains = <0x44 0x10>;
			resets = <0x31 0x09>;
			status = "disabled";
		};

		merge0@1c014000 {
			compatible = "mediatek,mt8188-disp-merge", "mediatek,mt8195-disp-merge";
			reg = <0x00 0x1c014000 0x00 0x1000>;
			clocks = <0x31 0x0b 0x3b 0x1e>;
			clock-names = "merge", "merge_async";
			interrupts = <0x00 0x290 0x04 0x00>;
			power-domains = <0x44 0x10>;
			mediatek,gce-client-reg = <0x78 0x04 0x4000 0x1000>;
		};

		dp-intf@1c015000 {
			compatible = "mediatek,mt8188-dp-intf";
			reg = <0x00 0x1c015000 0x00 0x1000>;
			clocks = <0x31 0x20 0x31 0x0c 0x2c 0x02>;
			clock-names = "pixel", "engine", "pll";
			interrupts = <0x00 0x291 0x04 0x00>;
			power-domains = <0x44 0x10>;
			status = "disabled";
		};

		mutex@1c016000 {
			compatible = "mediatek,mt8188-disp-mutex";
			reg = <0x00 0x1c016000 0x00 0x1000>;
			clocks = <0x31 0x03>;
			interrupts = <0x00 0x292 0x04 0x00>;
			power-domains = <0x44 0x10>;
			mediatek,gce-client-reg = <0x78 0x04 0x6000 0x1000>;
			mediatek,gce-events = <0x23e>;
		};

		postmask@1c01a000 {
			compatible = "mediatek,mt8188-disp-postmask", "mediatek,mt8192-disp-postmask";
			reg = <0x00 0x1c01a000 0x00 0x1000>;
			clocks = <0x31 0x13>;
			interrupts = <0x00 0x295 0x04 0x00>;
			power-domains = <0x44 0x10>;
			mediatek,gce-client-reg = <0x78 0x04 0xa000 0x1000>;

			ports {
				#address-cells = <0x01>;
				#size-cells = <0x00>;

				port@0 {
					reg = <0x00>;

					endpoint {
						remote-endpoint = <0x9d>;
						phandle = <0x90>;
					};
				};

				port@1 {
					reg = <0x01>;

					endpoint {
						remote-endpoint = <0x9e>;
						phandle = <0x91>;
					};
				};
			};
		};

		syscon@1c01d000 {
			compatible = "mediatek,mt8188-vdosys0", "syscon";
			reg = <0x00 0x1c01d000 0x00 0x1000>;
			#clock-cells = <0x01>;
			#reset-cells = <0x01>;
			mboxes = <0x78 0x00 0x04>;
			mediatek,gce-client-reg = <0x78 0x04 0xd000 0x1000>;
			phandle = <0x31>;

			port {
				#address-cells = <0x01>;
				#size-cells = <0x00>;

				endpoint@0 {
					reg = <0x00>;
					remote-endpoint = <0x9f>;
					phandle = <0x85>;
				};
			};
		};

		smi@1c022000 {
			compatible = "mediatek,mt8188-smi-larb";
			reg = <0x00 0x1c022000 0x00 0x1000>;
			clocks = <0x31 0x1c 0x31 0x1c>;
			clock-names = "apb", "smi";
			power-domains = <0x44 0x10>;
			mediatek,larb-id = <0x00>;
			mediatek,smi = <0x84>;
			phandle = <0xa0>;
		};

		smi@1c023000 {
			compatible = "mediatek,mt8188-smi-larb";
			reg = <0x00 0x1c023000 0x00 0x1000>;
			clocks = <0x31 0x1c 0x31 0x1c>;
			clock-names = "apb", "smi";
			power-domains = <0x44 0x10>;
			mediatek,larb-id = <0x01>;
			mediatek,smi = <0x7c>;
			phandle = <0x7d>;
		};

		smi@1c024000 {
			compatible = "mediatek,mt8188-smi-common-vdo";
			reg = <0x00 0x1c024000 0x00 0x1000>;
			clocks = <0x31 0x19 0x31 0x18>;
			clock-names = "apb", "smi";
			power-domains = <0x44 0x10>;
			phandle = <0x84>;
		};

		iommu@1c028000 {
			compatible = "mediatek,mt8188-iommu-vdo";
			reg = <0x00 0x1c028000 0x00 0x5000>;
			clocks = <0x31 0x1b>;
			clock-names = "bclk";
			interrupts = <0x00 0x2a1 0x04 0x00>;
			power-domains = <0x44 0x10>;
			#iommu-cells = <0x01>;
			mediatek,larbs = <0xa0 0xa1 0xa2 0xa3 0xa4>;
			phandle = <0x83>;
		};

		syscon@1c100000 {
			compatible = "mediatek,mt8188-vdosys1", "syscon";
			reg = <0x00 0x1c100000 0x00 0x1000>;
			#clock-cells = <0x01>;
			#reset-cells = <0x01>;
			mboxes = <0x78 0x01 0x04>;
			mediatek,gce-client-reg = <0x78 0x06 0x00 0x1000>;
			phandle = <0x3b>;

			port {
				#address-cells = <0x01>;
				#size-cells = <0x00>;

				endpoint@1 {
					reg = <0x01>;
					remote-endpoint = <0xa5>;
					phandle = <0xaa>;
				};
			};
		};

		mutex@1c101000 {
			compatible = "mediatek,mt8188-disp-mutex";
			reg = <0x00 0x1c101000 0x00 0x1000>;
			clocks = <0x3b 0x10>;
			interrupts = <0x00 0x1ee 0x04 0x00>;
			power-domains = <0x44 0x11>;
			mediatek,gce-client-reg = <0x78 0x06 0x1000 0x1000>;
			mediatek,gce-events = <0x2c5>;
		};

		smi@1c102000 {
			compatible = "mediatek,mt8188-smi-larb";
			reg = <0x00 0x1c102000 0x00 0x1000>;
			clocks = <0x3b 0x00 0x3b 0x00>;
			clock-names = "apb", "smi";
			power-domains = <0x44 0x11>;
			mediatek,larb-id = <0x02>;
			mediatek,smi = <0x84>;
			phandle = <0xa1>;
		};

		smi@1c103000 {
			compatible = "mediatek,mt8188-smi-larb";
			reg = <0x00 0x1c103000 0x00 0x1000>;
			clocks = <0x3b 0x01 0x3b 0x01>;
			clock-names = "apb", "smi";
			power-domains = <0x44 0x11>;
			mediatek,larb-id = <0x03>;
			mediatek,smi = <0x7c>;
			phandle = <0x7e>;
		};

		rdma@1c104000 {
			compatible = "mediatek,mt8188-vdo1-rdma", "mediatek,mt8195-vdo1-rdma";
			reg = <0x00 0x1c104000 0x00 0x1000>;
			clocks = <0x3b 0x05>;
			interrupts = <0x00 0x1ef 0x04 0x00>;
			iommus = <0x83 0x40>;
			power-domains = <0x44 0x11>;
			#dma-cells = <0x01>;
			mediatek,gce-client-reg = <0x78 0x06 0x4000 0x1000>;
		};

		rdma@1c105000 {
			compatible = "mediatek,mt8188-vdo1-rdma", "mediatek,mt8195-vdo1-rdma";
			reg = <0x00 0x1c105000 0x00 0x1000>;
			clocks = <0x3b 0x06>;
			interrupts = <0x00 0x1f0 0x04 0x00>;
			iommus = <0x79 0x60>;
			power-domains = <0x44 0x11>;
			#dma-cells = <0x01>;
			mediatek,gce-client-reg = <0x78 0x06 0x5000 0x1000>;
		};

		rdma@1c106000 {
			compatible = "mediatek,mt8188-vdo1-rdma", "mediatek,mt8195-vdo1-rdma";
			reg = <0x00 0x1c106000 0x00 0x1000>;
			clocks = <0x3b 0x07>;
			interrupts = <0x00 0x1f1 0x04 0x00>;
			iommus = <0x83 0x41>;
			power-domains = <0x44 0x11>;
			#dma-cells = <0x01>;
			mediatek,gce-client-reg = <0x78 0x06 0x6000 0x1000>;
		};

		rdma@1c107000 {
			compatible = "mediatek,mt8188-vdo1-rdma", "mediatek,mt8195-vdo1-rdma";
			reg = <0x00 0x1c107000 0x00 0x1000>;
			clocks = <0x3b 0x08>;
			interrupts = <0x00 0x1f2 0x04 0x00>;
			iommus = <0x79 0x61>;
			power-domains = <0x44 0x11>;
			#dma-cells = <0x01>;
			mediatek,gce-client-reg = <0x78 0x06 0x7000 0x1000>;
		};

		rdma@1c108000 {
			compatible = "mediatek,mt8188-vdo1-rdma", "mediatek,mt8195-vdo1-rdma";
			reg = <0x00 0x1c108000 0x00 0x1000>;
			clocks = <0x3b 0x11>;
			interrupts = <0x00 0x1f3 0x04 0x00>;
			iommus = <0x83 0x42>;
			power-domains = <0x44 0x11>;
			#dma-cells = <0x01>;
			mediatek,gce-client-reg = <0x78 0x06 0x8000 0x1000>;
		};

		rdma@1c109000 {
			compatible = "mediatek,mt8188-vdo1-rdma", "mediatek,mt8195-vdo1-rdma";
			reg = <0x00 0x1c109000 0x00 0x1000>;
			clocks = <0x3b 0x12>;
			interrupts = <0x00 0x1f4 0x04 0x00>;
			iommus = <0x79 0x62>;
			power-domains = <0x44 0x11>;
			#dma-cells = <0x01>;
			mediatek,gce-client-reg = <0x78 0x06 0x9000 0x1000>;
		};

		rdma@1c10a000 {
			compatible = "mediatek,mt8188-vdo1-rdma", "mediatek,mt8195-vdo1-rdma";
			reg = <0x00 0x1c10a000 0x00 0x1000>;
			clocks = <0x3b 0x13>;
			interrupts = <0x00 0x1f5 0x04 0x00>;
			iommus = <0x83 0x43>;
			power-domains = <0x44 0x11>;
			#dma-cells = <0x01>;
			mediatek,gce-client-reg = <0x78 0x06 0xa000 0x1000>;
		};

		rdma@1c10b000 {
			compatible = "mediatek,mt8188-vdo1-rdma", "mediatek,mt8195-vdo1-rdma";
			reg = <0x00 0x1c10b000 0x00 0x1000>;
			clocks = <0x3b 0x14>;
			interrupts = <0x00 0x1f6 0x04 0x00>;
			iommus = <0x79 0x63>;
			power-domains = <0x44 0x11>;
			#dma-cells = <0x01>;
			mediatek,gce-client-reg = <0x78 0x06 0xb000 0x1000>;
		};

		merge@1c10c000 {
			compatible = "mediatek,mt8188-disp-merge", "mediatek,mt8195-disp-merge";
			reg = <0x00 0x1c10c000 0x00 0x1000>;
			clocks = <0x3b 0x09 0x3b 0x18>;
			clock-names = "merge", "merge_async";
			interrupts = <0x00 0x1f7 0x04 0x00>;
			power-domains = <0x44 0x11>;
			resets = <0x3b 0x18>;
			mediatek,gce-client-reg = <0x78 0x06 0xc000 0x1000>;
			mediatek,merge-mute;
		};

		merge@1c10d000 {
			compatible = "mediatek,mt8188-disp-merge", "mediatek,mt8195-disp-merge";
			reg = <0x00 0x1c10d000 0x00 0x1000>;
			clocks = <0x3b 0x0a 0x3b 0x19>;
			clock-names = "merge", "merge_async";
			interrupts = <0x00 0x1f8 0x04 0x00>;
			power-domains = <0x44 0x11>;
			resets = <0x3b 0x19>;
			mediatek,gce-client-reg = <0x78 0x06 0xd000 0x1000>;
			mediatek,merge-mute;
		};

		merge@1c10e000 {
			compatible = "mediatek,mt8188-disp-merge", "mediatek,mt8195-disp-merge";
			reg = <0x00 0x1c10e000 0x00 0x1000>;
			clocks = <0x3b 0x0b 0x3b 0x1a>;
			clock-names = "merge", "merge_async";
			interrupts = <0x00 0x1f9 0x04 0x00>;
			power-domains = <0x44 0x11>;
			resets = <0x3b 0x1a>;
			mediatek,gce-client-reg = <0x78 0x06 0xe000 0x1000>;
			mediatek,merge-mute;
		};

		merge@1c10f000 {
			compatible = "mediatek,mt8188-disp-merge", "mediatek,mt8195-disp-merge";
			reg = <0x00 0x1c10f000 0x00 0x1000>;
			clocks = <0x3b 0x0c 0x3b 0x1b>;
			clock-names = "merge", "merge_async";
			interrupts = <0x00 0x1fa 0x04 0x00>;
			power-domains = <0x44 0x11>;
			resets = <0x3b 0x1b>;
			mediatek,gce-client-reg = <0x78 0x06 0xf000 0x1000>;
			mediatek,merge-mute;
		};

		merge@1c110000 {
			compatible = "mediatek,mt8188-disp-merge", "mediatek,mt8195-disp-merge";
			reg = <0x00 0x1c110000 0x00 0x1000>;
			clocks = <0x3b 0x0d 0x3b 0x1c>;
			clock-names = "merge", "merge_async";
			interrupts = <0x00 0x1fb 0x04 0x00>;
			power-domains = <0x44 0x11>;
			resets = <0x3b 0x1c>;
			mediatek,gce-client-reg = <0x78 0x07 0x00 0x1000>;
			mediatek,merge-fifo-en;

			ports {
				#address-cells = <0x01>;
				#size-cells = <0x00>;

				port@0 {
					#address-cells = <0x01>;
					#size-cells = <0x00>;
					reg = <0x00>;

					endpoint@1 {
						reg = <0x01>;
						remote-endpoint = <0xa6>;
						phandle = <0xab>;
					};
				};

				port@1 {
					#address-cells = <0x01>;
					#size-cells = <0x00>;
					reg = <0x01>;

					endpoint@1 {
						reg = <0x01>;
						remote-endpoint = <0xa7>;
						phandle = <0xa8>;
					};
				};
			};
		};

		dp-intf@1c113000 {
			compatible = "mediatek,mt8188-dp-intf";
			reg = <0x00 0x1c113000 0x00 0x1000>;
			clocks = <0x3b 0x3a 0x3b 0x15 0x2c 0x03>;
			clock-names = "pixel", "engine", "pll";
			interrupts = <0x00 0x201 0x04 0x00>;
			power-domains = <0x44 0x11>;
			status = "okay";

			ports {
				#address-cells = <0x01>;
				#size-cells = <0x00>;

				port@0 {
					#address-cells = <0x01>;
					#size-cells = <0x00>;
					reg = <0x00>;

					endpoint@1 {
						reg = <0x01>;
						remote-endpoint = <0xa8>;
						phandle = <0xa7>;
					};
				};

				port@1 {
					#address-cells = <0x01>;
					#size-cells = <0x00>;
					reg = <0x01>;

					endpoint@1 {
						reg = <0x01>;
						remote-endpoint = <0xa9>;
						phandle = <0xae>;
					};
				};
			};
		};

		ethdr@1c114000 {
			compatible = "mediatek,mt8188-disp-ethdr", "mediatek,mt8195-disp-ethdr";
			reg = <0x00 0x1c114000 0x00 0x1000 0x00 0x1c115000 0x00 0x1000 0x00 0x1c117000 0x00 0x1000 0x00 0x1c119000 0x00 0x1000 0x00 0x1c11a000 0x00 0x1000 0x00 0x1c11b000 0x00 0x1000 0x00 0x1c11c000 0x00 0x1000>;
			reg-names = "mixer", "vdo_fe0", "vdo_fe1", "gfx_fe0", "gfx_fe1", "vdo_be", "adl_ds";
			clocks = <0x3b 0x30 0x3b 0x2b 0x3b 0x2e 0x3b 0x2c 0x3b 0x2f 0x3b 0x2d 0x3b 0x3c 0x3b 0x31 0x3b 0x32 0x3b 0x33 0x3b 0x34 0x3b 0x35 0x2d 0x05>;
			clock-names = "mixer", "vdo_fe0", "vdo_fe1", "gfx_fe0", "gfx_fe1", "vdo_be", "adl_ds", "vdo_fe0_async", "vdo_fe1_async", "gfx_fe0_async", "gfx_fe1_async", "vdo_be_async", "ethdr_top";
			interrupts = <0x00 0x236 0x04 0x00>;
			iommus = <0x79 0x64 0x79 0x65>;
			power-domains = <0x44 0x11>;
			resets = <0x3b 0x31 0x3b 0x32 0x3b 0x33 0x3b 0x34 0x3b 0x35>;
			mediatek,gce-client-reg = <0x78 0x07 0x4000 0x1000 0x78 0x07 0x5000 0x1000 0x78 0x07 0x7000 0x1000 0x78 0x07 0x9000 0x1000 0x78 0x07 0xa000 0x1000 0x78 0x07 0xb000 0x1000 0x78 0x07 0xc000 0x1000>;

			ports {
				#address-cells = <0x01>;
				#size-cells = <0x00>;

				port@0 {
					#address-cells = <0x01>;
					#size-cells = <0x00>;
					reg = <0x00>;

					endpoint@1 {
						reg = <0x01>;
						remote-endpoint = <0xaa>;
						phandle = <0xa5>;
					};
				};

				port@1 {
					#address-cells = <0x01>;
					#size-cells = <0x00>;
					reg = <0x01>;

					endpoint@1 {
						reg = <0x01>;
						remote-endpoint = <0xab>;
						phandle = <0xa6>;
					};
				};
			};
		};

		padding@1c11d000 {
			compatible = "mediatek,mt8188-disp-padding";
			reg = <0x00 0x1c11d000 0x00 0x1000>;
			clocks = <0x3b 0x1f>;
			power-domains = <0x44 0x11>;
			mediatek,gce-client-reg = <0x78 0x07 0xd000 0x1000>;
		};

		padding@1c11e000 {
			compatible = "mediatek,mt8188-disp-padding";
			reg = <0x00 0x1c11e000 0x00 0x1000>;
			clocks = <0x3b 0x20>;
			power-domains = <0x44 0x11>;
			mediatek,gce-client-reg = <0x78 0x07 0xe000 0x1000>;
		};

		padding@1c11f000 {
			compatible = "mediatek,mt8188-disp-padding";
			reg = <0x00 0x1c11f000 0x00 0x1000>;
			clocks = <0x3b 0x21>;
			power-domains = <0x44 0x11>;
			mediatek,gce-client-reg = <0x78 0x07 0xf000 0x1000>;
		};

		padding@1c120000 {
			compatible = "mediatek,mt8188-disp-padding";
			reg = <0x00 0x1c120000 0x00 0x1000>;
			clocks = <0x3b 0x22>;
			power-domains = <0x44 0x11>;
			mediatek,gce-client-reg = <0x78 0x08 0x00 0x1000>;
		};

		padding@1c121000 {
			compatible = "mediatek,mt8188-disp-padding";
			reg = <0x00 0x1c121000 0x00 0x1000>;
			clocks = <0x3b 0x23>;
			power-domains = <0x44 0x11>;
			mediatek,gce-client-reg = <0x78 0x08 0x1000 0x1000>;
		};

		padding@1c122000 {
			compatible = "mediatek,mt8188-disp-padding";
			reg = <0x00 0x1c122000 0x00 0x1000>;
			clocks = <0x3b 0x24>;
			power-domains = <0x44 0x11>;
			mediatek,gce-client-reg = <0x78 0x08 0x2000 0x1000>;
		};

		padding@1c123000 {
			compatible = "mediatek,mt8188-disp-padding";
			reg = <0x00 0x1c123000 0x00 0x1000>;
			clocks = <0x3b 0x25>;
			power-domains = <0x44 0x11>;
			mediatek,gce-client-reg = <0x78 0x08 0x3000 0x1000>;
		};

		padding@1c124000 {
			compatible = "mediatek,mt8188-disp-padding";
			reg = <0x00 0x1c124000 0x00 0x1000>;
			clocks = <0x3b 0x26>;
			power-domains = <0x44 0x11>;
			mediatek,gce-client-reg = <0x78 0x08 0x4000 0x1000>;
		};

		edp-tx@1c500000 {
			compatible = "mediatek,mt8188-edp-tx";
			reg = <0x00 0x1c500000 0x00 0x8000>;
			interrupts = <0x00 0x2a4 0x04 0x00>;
			nvmem-cells = <0xac>;
			nvmem-cell-names = "dp_calibration_data";
			power-domains = <0x44 0x13>;
			max-linkrate-mhz = <0x1fa4>;
			status = "disabled";
		};

		dp-tx@1c600000 {
			compatible = "mediatek,mt8188-dp-tx";
			reg = <0x00 0x1c600000 0x00 0x8000>;
			interrupts = <0x00 0x1ca 0x04 0x00>;
			nvmem-cells = <0xac>;
			nvmem-cell-names = "dp_calibration_data";
			power-domains = <0x44 0x12>;
			max-linkrate-mhz = <0x1518>;
			status = "okay";
			pinctrl-names = "default";
			pinctrl-0 = <0xad>;
			#sound-dai-cells = <0x00>;
			phandle = <0x1e>;

			ports {
				#address-cells = <0x01>;
				#size-cells = <0x00>;

				port@0 {
					reg = <0x00>;

					endpoint {
						remote-endpoint = <0xae>;
						phandle = <0xa9>;
					};
				};

				port@1 {
					reg = <0x01>;

					endpoint {
						data-lanes = <0x00 0x01 0x02 0x03>;
					};
				};
			};
		};
	};

	backlight-lcd0 {
		compatible = "pwm-backlight";
		brightness-levels = <0x00 0x3ff>;
		default-brightness-level = <0x240>;
		enable-gpios = <0x2a 0x01 0x00>;
		num-interpolated-steps = <0x3ff>;
		power-supply = <0xaf>;
		pwms = <0xb0 0x00 0x7a120>;
		phandle = <0x95>;
	};

	chosen {
		stdout-path = "serial0:115200n8";
	};

	dmic-codec {
		compatible = "dmic-codec";
		num-channels = <0x02>;
		wakeup-delay-ms = <0x64>;
	};

	memory@40000000 {
		device_type = "memory";
		reg = <0x00 0x40000000 0x00 0x00>;
	};

	regulator-pp1800-ldo-z1 {
		compatible = "regulator-fixed";
		regulator-name = "pp1800_ldo_z1";
		regulator-always-on;
		regulator-boot-on;
		regulator-min-microvolt = <0x1b7740>;
		regulator-max-microvolt = <0x1b7740>;
		vin-supply = <0x68>;
	};

	regulator-pp3300-s3 {
		compatible = "regulator-fixed";
		regulator-name = "pp3300_s3";
		regulator-always-on;
		regulator-boot-on;
		regulator-min-microvolt = <0x325aa0>;
		regulator-max-microvolt = <0x325aa0>;
		vin-supply = <0x68>;
		phandle = <0x58>;
	};

	regulator-pp3300-z1 {
		compatible = "regulator-fixed";
		regulator-name = "pp3300_z1";
		regulator-always-on;
		regulator-boot-on;
		regulator-min-microvolt = <0x325aa0>;
		regulator-max-microvolt = <0x325aa0>;
		vin-supply = <0xaf>;
		phandle = <0x68>;
	};

	regulator-pp3300-wlan {
		compatible = "regulator-fixed";
		regulator-name = "pp3300_wlan";
		regulator-always-on;
		regulator-min-microvolt = <0x325aa0>;
		regulator-max-microvolt = <0x325aa0>;
		enable-active-high;
		gpio = <0x2a 0x0c 0x00>;
		pinctrl-0 = <0xb1>;
		pinctrl-names = "default";
		vin-supply = <0x68>;
		phandle = <0xb5>;
	};

	regulator-pp3300-mipi-tchscr {
		compatible = "regulator-fixed";
		regulator-name = "pp3300_mipi_tchscr";
		regulator-always-on;
		regulator-boot-on;
		regulator-min-microvolt = <0x325aa0>;
		regulator-max-microvolt = <0x325aa0>;
		enable-active-high;
		gpio = <0x2a 0x90 0x00>;
		vin-supply = <0x68>;
		phandle = <0xb6>;
	};

	regulator-pp4200-s5 {
		compatible = "regulator-fixed";
		regulator-name = "pp4200_s5";
		regulator-always-on;
		regulator-boot-on;
		regulator-min-microvolt = <0x401640>;
		regulator-max-microvolt = <0x401640>;
		vin-supply = <0xaf>;
	};

	regulator-pp5000-z1 {
		compatible = "regulator-fixed";
		regulator-name = "pp5000_z1";
		regulator-always-on;
		regulator-boot-on;
		regulator-min-microvolt = <0x4c4b40>;
		regulator-max-microvolt = <0x4c4b40>;
		vin-supply = <0xaf>;
		phandle = <0xb2>;
	};

	regulator-pp5000-usb-vbus {
		compatible = "regulator-fixed";
		regulator-name = "pp5000_usb_vbus";
		regulator-min-microvolt = <0x4c4b40>;
		regulator-max-microvolt = <0x4c4b40>;
		enable-active-high;
		gpio = <0x2a 0x96 0x00>;
		vin-supply = <0xb2>;
		phandle = <0x59>;
	};

	regulator-ppvar-sys {
		compatible = "regulator-fixed";
		regulator-name = "ppvar_sys";
		regulator-always-on;
		regulator-boot-on;
		phandle = <0xaf>;
	};

	regulator-ppvar-mipi-disp-avdd {
		compatible = "regulator-fixed";
		regulator-name = "ppvar_mipi_disp_avdd";
		enable-active-high;
		gpio = <0x2a 0x03 0x00>;
		pinctrl-names = "default";
		pinctrl-0 = <0xb3>;
		vin-supply = <0xb2>;
		phandle = <0x96>;
	};

	regulator-ppvar-mipi-disp-avee {
		compatible = "regulator-fixed";
		regulator-name = "ppvar_mipi_disp_avee";
		regulator-enable-ramp-delay = <0x2710>;
		enable-active-high;
		gpio = <0x2a 0x04 0x00>;
		pinctrl-names = "default";
		pinctrl-0 = <0xb4>;
		vin-supply = <0xb2>;
		phandle = <0x97>;
	};

	reserved-memory {
		#address-cells = <0x02>;
		#size-cells = <0x02>;
		ranges;

		memory@50000000 {
			compatible = "shared-dma-pool";
			reg = <0x00 0x50000000 0x00 0x800000>;
			no-map;
			phandle = <0x42>;
		};

		memory@55000000 {
			compatible = "shared-dma-pool";
			reg = <0x00 0x55000000 0x00 0x1400000>;
		};

		memory@60000000 {
			compatible = "shared-dma-pool";
			reg = <0x00 0x60000000 0x00 0xf00000>;
			no-map;
			phandle = <0x4a>;
		};

		memory@60f00000 {
			compatible = "shared-dma-pool";
			reg = <0x00 0x60f00000 0x00 0x100000>;
			no-map;
			phandle = <0x46>;
		};

		memory@61000000 {
			compatible = "shared-dma-pool";
			reg = <0x00 0x61000000 0x00 0x100000>;
			no-map;
			phandle = <0x49>;
		};
	};
};
